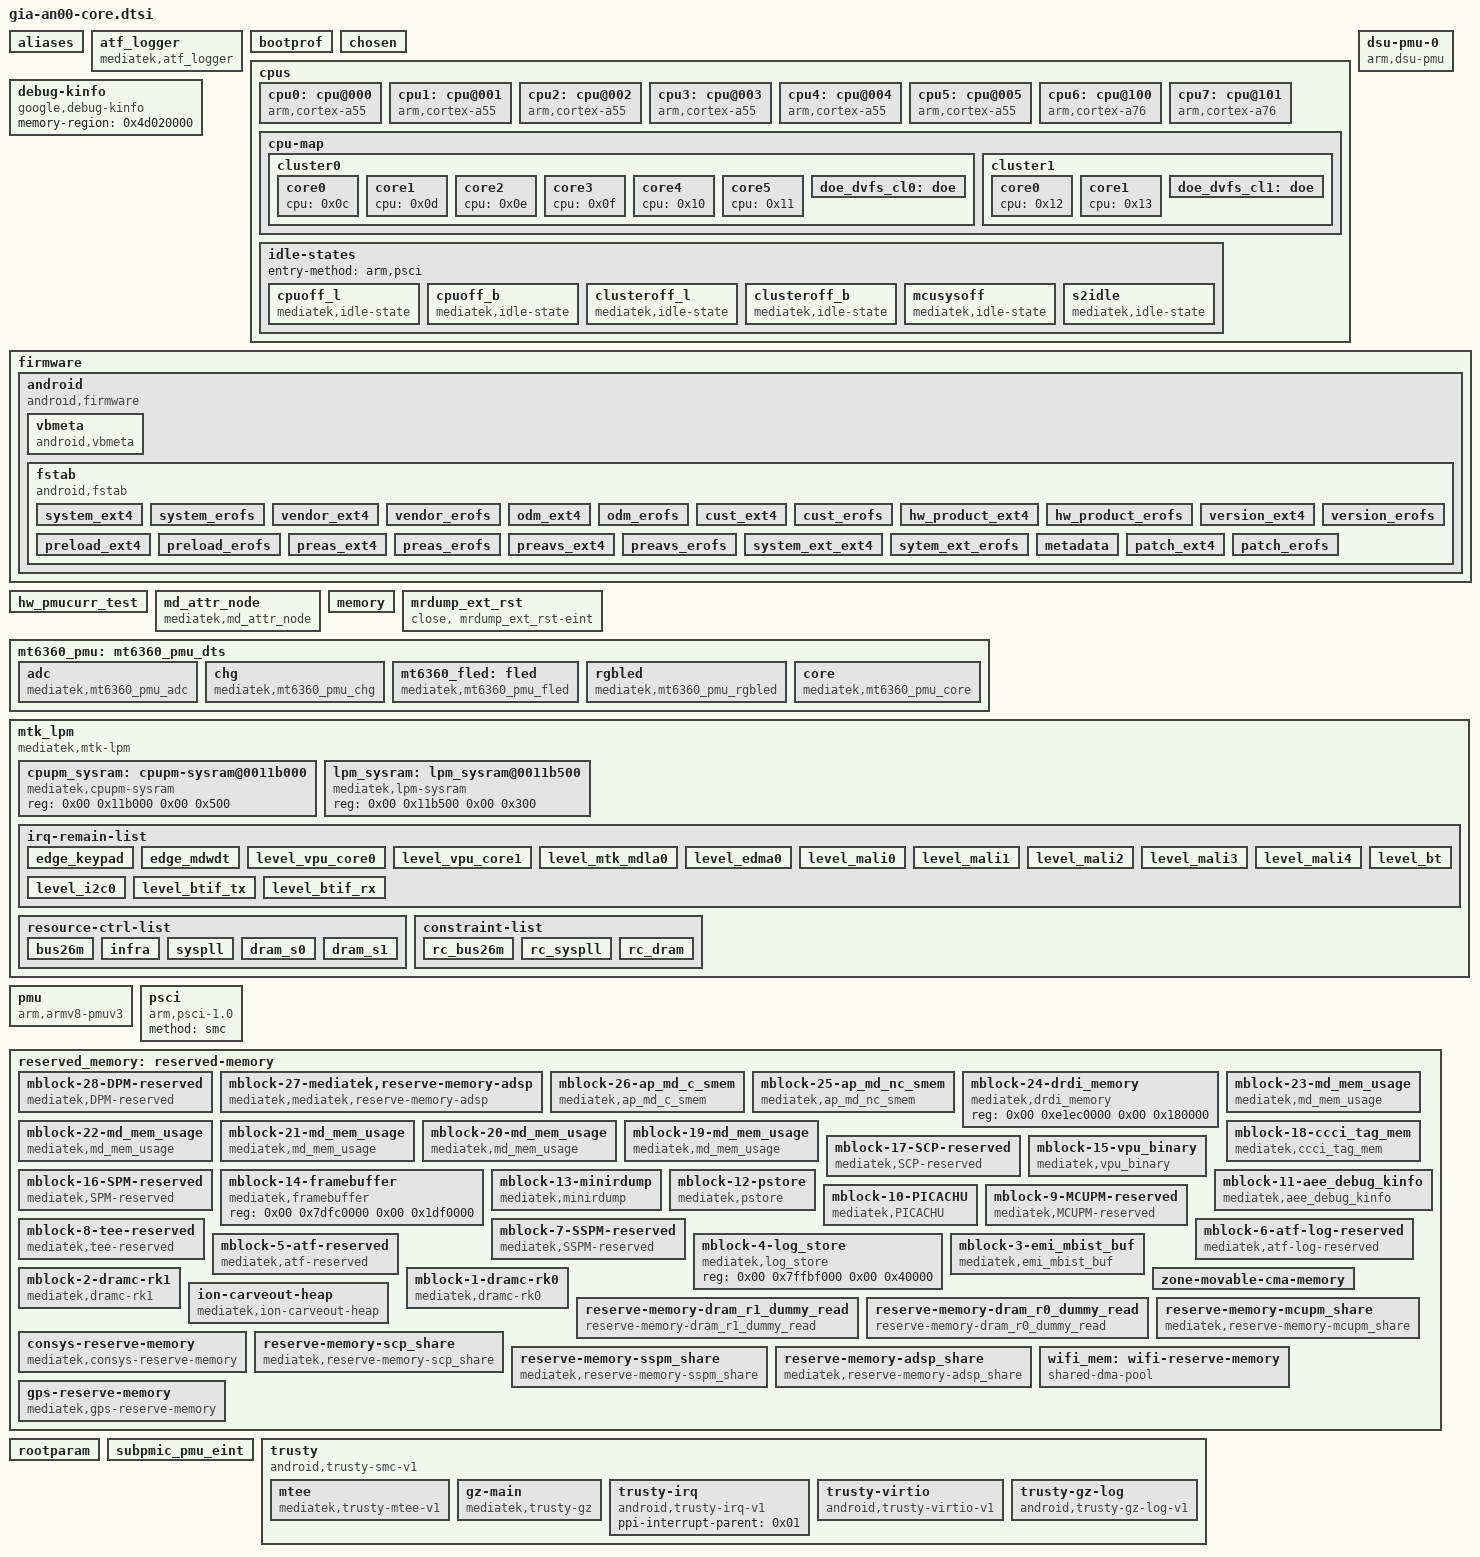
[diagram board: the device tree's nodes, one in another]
// SPDX-License-Identifier: GPL-2.0
/*
 * HONOR GIA-AN00 / MT6877V/ZA 设备树分片
 * 由实机反编译 device.dts 自动还原，节点内容保持原样
 */

/* 20 个顶层节点 */

	aliases {
			ovl0 = "/disp_ovl0@14005000";
			ovl3 = "/disp_ovl0_2l@14006000";
			ovl4 = "/disp_ovl1_2l@1401f000";
			rdma0 = "/disp_rdma0@14007000";
			dsi0 = "/dsi@14013000";
			ccorr0 = "/disp_ccorr0@1400b000";
			ccorr1 = "/disp_ccorr1@1400a000";
			mtk-msdc0 = "/msdc@11230000";
			mtk-msdc1 = "/msdc@11240000";
		};

	atf_logger {
			compatible = "mediatek,atf_logger";
		};

	bootprof {
			lk_logo_t = <0x3a7>;
			lk_t = <0x1619>;
			pl_t = <0x108f>;
		};

	chosen: chosen {
			mrdump,lk = "MRDUMP11";
			mrdump,cblock = <0x11e000 0x2000>;
			mrdump,ddr_rsv = "yes";
			aee,enable = "mini";
			atag,chipid = <0x6000000 0x59090000 0x8a0000 0xca0000 0x00>;
			linux,initrd-end = <0x5129b5be>;
			dfd,cache_dump_support = <0x01>;
			dfd,base_addr_msb = <0x8e000000>;
			dfd,base_addr = <0x00 0x8e000000>;
			non_secure_sram = <0x201100 0xe00000>;
			atag,masp = <0x16000000 0x66080041 0x11000000 0x11000000 0x1000000 0x00 0xa439f532 0xfdd77274 0xd1c98a0b 0x44a3db6c 0x31413532 0x41333637 0x43423132 0x43343538 0x992c97b6 0x168ee0c8 0x00 0x00 0x00 0x00 0x00 0x00>;
			atag,ptp = <0x6000000 0x8004154 0x00 0x00 0x00 0x00>;
			ccci,modem_info_v2 = <0xffbf 0x00 0x800a0000 0x00 0x3000000 0x14000000 0x1000000 0x00 0x00 0x00 0x00 0x00>;
			atag,mdinfo = <0x3000000 0x6080041 0x00>;
			atag,videolfb = <0xfc7d 0x00 0x1000000 0xa4170000 0xdf01 0x6c63646b 0x69745f6d 0x746b5f63 0x6f6d6d6f 0x6e5f7061 0x6e656c5f 0x64727600 0x40040000 0x38041b00 0x60091b00>;
			atag,devinfo = <0xdc000000 0x00 0x00 0x00 0x00 0x9a0800 0xc042 0x00 0x1000000 0x59090000 0x59090000 0x400ab56 0x40040000 0xaf290fd8 0x3d9bc8c 0x9179c5e9 0xd5517569 0x00 0xca0000 0x59090000 0x59090000 0x59090000 0x00 0x00 0x00 0x00 0x00 0x1000000 0x4e000000 0x59090000 0x00 0x1000000 0x00 0x7d400300 0x84000000 0x00 0x00 0x00 0x00 0x00 0x00 0x00 0x00 0x59090000 0x00 0x00 0x00 0x00 0x59090000 0x59090000 0xaa000000 0x2000200 0x00 0x9924b2d6 0xc4348f85 0xea24bdc7 0xf4348991 0xea24b3c0 0xf4348e93 0x17249f2f 0x4b246f68 0xffbf0000 0xffbf 0xffbfffbf 0xffbfffbf 0xc070c070 0x00 0x00 0x00 0x00 0x00 0x00 0x00 0x00 0x00 0x00 0x59090000 0x00 0x00 0x00 0x00 0x992c97b6 0xc5d1b92d 0x873c8d2a 0x7a4124e2 0x168ee0c8 0x2d515b4e 0x439dfcc2 0xa94b447d 0x00 0x00 0x00 0x00 0x3000000 0x00 0x00 0x00 0x00 0x00 0x59090000 0x59090000 0x10002020 0x22000015 0x16151515 0x27220000 0x80b5d65a 0x00 0x00 0x8081200 0x10000000 0xc4186384 0x86184 0x18238c 0x80182384 0xfd819700 0x00 0x00 0x3c 0xf68a0000 0xea8a000a 0xdc8800a1 0x00 0x00 0x00 0x00 0x00 0x00 0x00 0x59090000 0x59090000 0x59090000 0x00 0x00 0x00 0xa000000 0x75ed7d26 0xc8b586d6 0xf8c80820 0x3848b5 0x00 0x00 0x6700700 0xb200a00 0x59090000 0x59090000 0x59090000 0x3501c80 0x59090000 0x59090000 0x59090000 0x59090000 0x00 0x00 0x00 0x00 0x00 0x00 0x59090000 0x59090000 0x59090000 0x59090000 0x00 0x00 0x00 0x00 0x00 0x7014a018 0x4c1c2e14 0x7b18631c 0x6e3f6d3e 0x6d3e6c3f 0x12360000 0x3f3f0000 0x6576 0x79757404 0x7cfc0000 0x8b3a7b83 0xaf76b076 0xab74ab74 0x00 0x00 0x00 0x4fb47105 0x76688187 0x24c3f006 0x59090000 0x59090000 0x59090000 0x59090000 0x59090000 0x59090000 0xba880000 0x8c88000a 0xa1880079 0x418a0000 0x478a000a 0x488a007b 0x188a0000 0x198a0000 0xfe890000 0xed890000 0x5d890000 0x4f890000 0xac890000 0xb9890000 0xbb890000 0xa60a0000 0xc70a0000 0x8f0a0000 0x00 0x00 0x990c0000 0x59090000 0xcd7b97aa 0x63cb00cf 0x39cf1401 0xa049d243 0x89288a39 0xd6065517 0x9448968f 0x1bd66462>;
			atag,mem = <0x6000000 0x2004254 0x00 0x00 0x00 0x00 0x6000000 0x2004254 0x00 0x00 0x00 0x00>;
			atag,two_sec_reboot = [30];
			atag,boot_voltage = <0x33383639>;
			log_store = <0xdf1100 0x10000>;
			ram_console = <0xd01100 0x80000 0x1000000 0xc00e0000>;
			atag,shutdown_time = [30];
			atag,fg_swocv_i = [2d 33 33 38 35];
			atag,fg_swocv_v = [33 38 34 37 39];
			atag,imix_r = <0x4f000000>;
			atag,boot = <0x3000000 0x2080041 0x00 0x2000000>;
			linux,initrd-start = <0x51100000>;
			plat_dbg_info,size = <0x5c 0x2c 0x10>;
			plat_dbg_info,base = <0x11d80c 0x11d868 0x11d894>;
			plat_dbg_info,key = <0xd8a3 0xe31c 0xdb45>;
			plat_dbg_info,max = <0x03>;
			bootargs = "root=/dev/ram \t\t\tvmalloc=400M slub_debug=OFZPU swiotlb=noforce \t\t\tinitcall_debug=1 \t\t\tfirmware_class.path=/vendor/firmware \t\t\tpage_owner=on has_battery_removed=0 ramoops.mem_address=0x48090000 ramoops.mem_size=0xe0000 ramoops.pmsg_size=0x10000 ramoops.console_size=0x40000 loop.max_part=7 androidboot.boot_devices=bootdevice,soc/11230000.mmc,11230000.mmc,soc/11230000.msdc,11230000.msdc,soc/11270000.ufshci,11270000.ufshci androidboot.powerkey_restart_type=0 ramoops.mem_address=0x48090000 ramoops.mem_size=0xe0000 ramoops.pmsg_size=0x10000 ramoops.console_size=0x40000 battery_nv_sn=0000000000000000 battery_ic=5,6A922A322318AE3801002900 battery_info=AC,0,3620ACM228A0A685 battery_cert=0,0000  bootopt=64S3,32N2,64N2 buildvariant=user root=/dev/ram androidboot.slot_suffix=_b androidboot.slot=b androidboot.veritymode=enforcing androidboot.vbmeta.avb_version=1.2 root=/dev/ram androidboot.verifiedbootstate=orange androidboot.swtype=normal fg_cali=0xedd4e,0x0,0xf4734,0x0,0x0,0x0,0x0,0x0 androidboot.hwsim=default  start_mcs_flag=false TP_COLOR=0 devmodel=GIA-AN00 vendorcountry=all/cn oba_version=20260410061949_OBA_VERSION androidboot.atm=disabled enter_recovery=0 usb_macbt=normal boot_detector_enable=1  boot_recovery_enable=1  androidboot.meta_log_disable=0 efuse_sla_status=1 mtk_printk_ctrl.disable_uart=1 androidboot.serialno=0000000000000000 androidboot.product.hardware.sku=GIA-AN00 userlock=locked  androidboot.oemmode=rd    androidboot.bootreason=normalboot reboot_reason=normalboot gpt=1 usb2jtag_mode=0 androidboot.dtb_idx=0 androidboot.dtbo_idx=6";
			kaslr-seed = <0x00 0x00>;
			phandle = <0xe4>;
			atag,videolfb-fb_base_l = "~`P";
			atag,videolfb-fb_base_h = <0x00>;
			atag,videolfb-islcmfound = <0x01>;
			atag,videolfb-islcm_inited = <0x00>;
			atag,videolfb-fps = <0x1770>;
			atag,videolfb-vramSize = <0x1be0000>;
			atag,videolfb-lcmname = "nt35595_fhd_dsi_cmd_truly_nt50358_drv";
		};

	cpus {
			#address-cells = <0x01>;
			#size-cells = <0x00>;
	
			cpu0: cpu@000 {
				device_type = "cpu";
				compatible = "arm,cortex-a55";
				reg = <0x00>;
				enable-method = "psci";
				clock-frequency = <0x77359400>;
				cpu-idle-states = <0x06 0x07 0x08 0x09>;
				phandle = <0x0c>;
			};
	
			cpu1: cpu@001 {
				device_type = "cpu";
				compatible = "arm,cortex-a55";
				reg = <0x100>;
				enable-method = "psci";
				clock-frequency = <0x77359400>;
				cpu-idle-states = <0x06 0x07 0x08 0x09>;
				phandle = <0x0d>;
			};
	
			cpu2: cpu@002 {
				device_type = "cpu";
				compatible = "arm,cortex-a55";
				reg = <0x200>;
				enable-method = "psci";
				clock-frequency = <0x77359400>;
				cpu-idle-states = <0x06 0x07 0x08 0x09>;
				phandle = <0x0e>;
			};
	
			cpu3: cpu@003 {
				device_type = "cpu";
				compatible = "arm,cortex-a55";
				reg = <0x300>;
				enable-method = "psci";
				clock-frequency = <0x77359400>;
				cpu-idle-states = <0x06 0x07 0x08 0x09>;
				phandle = <0x0f>;
			};
	
			cpu4: cpu@004 {
				device_type = "cpu";
				compatible = "arm,cortex-a55";
				reg = <0x400>;
				enable-method = "psci";
				clock-frequency = <0x77359400>;
				cpu-idle-states = <0x06 0x07 0x08 0x09>;
				phandle = <0x10>;
			};
	
			cpu5: cpu@005 {
				device_type = "cpu";
				compatible = "arm,cortex-a55";
				reg = <0x500>;
				enable-method = "psci";
				clock-frequency = <0x77359400>;
				cpu-idle-states = <0x06 0x07 0x08 0x09>;
				phandle = <0x11>;
			};
	
			cpu6: cpu@100 {
				device_type = "cpu";
				compatible = "arm,cortex-a76";
				reg = <0x600>;
				enable-method = "psci";
				clock-frequency = <0x77359400>;
				cpu-idle-states = <0x0a 0x0b 0x08 0x09>;
				phandle = <0x12>;
			};
	
			cpu7: cpu@101 {
				device_type = "cpu";
				compatible = "arm,cortex-a76";
				reg = <0x700>;
				enable-method = "psci";
				clock-frequency = <0x77359400>;
				cpu-idle-states = <0x0a 0x0b 0x08 0x09>;
				phandle = <0x13>;
			};
	
			cpu-map {
	
				cluster0 {
	
					core0 {
						cpu = <0x0c>;
					};
	
					core1 {
						cpu = <0x0d>;
					};
	
					core2 {
						cpu = <0x0e>;
					};
	
					core3 {
						cpu = <0x0f>;
					};
	
					core4 {
						cpu = <0x10>;
					};
	
					core5 {
						cpu = <0x11>;
					};
	
					doe_dvfs_cl0: doe {
						phandle = <0xe5>;
					};
				};
	
				cluster1 {
	
					core0 {
						cpu = <0x12>;
					};
	
					core1 {
						cpu = <0x13>;
					};
	
					doe_dvfs_cl1: doe {
						phandle = <0xe6>;
					};
				};
			};
	
			idle-states {
				entry-method = "arm,psci";
	
				cpuoff_l: cpuoff_l {
					compatible = "mediatek,idle-state";
					arm,psci-suspend-param = <0x10001>;
					local-timer-stop;
					entry-latency-us = <0x32>;
					exit-latency-us = <0x64>;
					min-residency-us = <0x640>;
					phandle = <0x06>;
				};
	
				cpuoff_b: cpuoff_b {
					compatible = "mediatek,idle-state";
					arm,psci-suspend-param = <0x10001>;
					local-timer-stop;
					entry-latency-us = <0x32>;
					exit-latency-us = <0x64>;
					min-residency-us = <0x578>;
					phandle = <0x0a>;
				};
	
				clusteroff_l: clusteroff_l {
					compatible = "mediatek,idle-state";
					arm,psci-suspend-param = <0x1010001>;
					local-timer-stop;
					entry-latency-us = <0x64>;
					exit-latency-us = <0xfa>;
					min-residency-us = <0x834>;
					phandle = <0x07>;
				};
	
				clusteroff_b: clusteroff_b {
					compatible = "mediatek,idle-state";
					arm,psci-suspend-param = <0x1010001>;
					local-timer-stop;
					entry-latency-us = <0x64>;
					exit-latency-us = <0xfa>;
					min-residency-us = <0x76c>;
					phandle = <0x0b>;
				};
	
				mcusysoff: mcusysoff {
					compatible = "mediatek,idle-state";
					arm,psci-suspend-param = <0x1010002>;
					local-timer-stop;
					entry-latency-us = <0x12c>;
					exit-latency-us = <0x4b0>;
					min-residency-us = <0xa28>;
					phandle = <0x08>;
				};
	
				s2idle: s2idle {
					compatible = "mediatek,idle-state";
					arm,psci-suspend-param = <0x1010100>;
					local-timer-stop;
					entry-latency-us = <0x1f4>;
					exit-latency-us = <0x578>;
					min-residency-us = <0xffffffff>;
					phandle = <0x09>;
				};
			};
		};

	debug-kinfo {
			memory-region = <0x4d020000>;
			compatible = "google,debug-kinfo";
		};

	dsu-pmu-0 {
			compatible = "arm,dsu-pmu";
			interrupts = <0x00 0x12 0x04>;
			cpus = <0x0c 0x0d 0x0e 0x0f 0x10 0x11 0x12 0x13>;
		};

	firmware {
	
			android {
				mode = "normal";
				serialno = "0000000000000000";
				hardware = "mt6877";
				vbmeta.digest = "26cabf14be922ae3c91020e367ab8466afb57b97a70f36fd0d32d0bc6ac9ac50";
				vbmeta.size = "30592";
				vbmeta.hash_alg = "sha256";
				compatible = "android,firmware";
	
				vbmeta {
					compatible = "android,vbmeta";
					parts = "vbmeta,boot,ramdisk,eng_system,eng_vendor,vbmeta_system,vbmeta_vendor,vbmeta_odm,vbmeta_hw_product,vbmeta_preas,vbmeta_preavs,vbmeta_cust,vbmeta_version,vbmeta_preload,vbmeta_system_ext";
					ta_parts = "boot,ramdisk,vbmeta_system,vbmeta_vendor,vbmeta_odm,vbmeta_hw_product,vbmeta_preas,vbmeta_preavs,vbmeta_cust,vbmeta_system_ext";
				};
	
				fstab {
					compatible = "android,fstab";
	
					system_ext4 {
						mnt_point = "/system";
						dev = "system";
						type = "ext4";
						mnt_flags = "ro";
						fsmgr_flags = "wait,logical,slotselect,first_stage_mount,avb";
						status = "ok";
					};
	
					system_erofs {
						mnt_point = "/system";
						dev = "system";
						type = "erofs";
						mnt_flags = "ro";
						fsmgr_flags = "wait,logical,slotselect,first_stage_mount,avb";
						status = "ok";
					};
	
					vendor_ext4 {
						mnt_point = "/vendor";
						dev = "vendor";
						type = "ext4";
						mnt_flags = "ro";
						fsmgr_flags = "wait,logical,slotselect,first_stage_mount,avb";
						status = "ok";
					};
	
					vendor_erofs {
						mnt_point = "/vendor";
						dev = "vendor";
						type = "erofs";
						mnt_flags = "ro";
						fsmgr_flags = "wait,logical,slotselect,first_stage_mount,avb";
						status = "ok";
					};
	
					odm_ext4 {
						mnt_point = "/odm";
						dev = "odm";
						type = "ext4";
						mnt_flags = "ro";
						fsmgr_flags = "wait,logical,slotselect,first_stage_mount,avb";
						status = "ok";
					};
	
					odm_erofs {
						mnt_point = "/odm";
						dev = "odm";
						type = "erofs";
						mnt_flags = "ro";
						fsmgr_flags = "wait,logical,slotselect,first_stage_mount,avb";
						status = "ok";
					};
	
					cust_ext4 {
						mnt_point = "/cust";
						dev = "cust";
						type = "ext4";
						mnt_flags = "ro";
						fsmgr_flags = "wait,nofail,logical,slotselect,first_stage_mount,avb";
						status = "ok";
					};
	
					cust_erofs {
						mnt_point = "/cust";
						dev = "cust";
						type = "erofs";
						mnt_flags = "ro";
						fsmgr_flags = "wait,nofail,logical,slotselect,first_stage_mount,avb";
						status = "ok";
					};
	
					hw_product_ext4 {
						mnt_point = "/product_h";
						dev = "hw_product";
						type = "ext4";
						mnt_flags = "ro";
						fsmgr_flags = "wait,nofail,logical,slotselect,first_stage_mount,avb";
						status = "ok";
					};
	
					hw_product_erofs {
						mnt_point = "/product_h";
						dev = "hw_product";
						type = "erofs";
						mnt_flags = "ro";
						fsmgr_flags = "wait,nofail,logical,slotselect,first_stage_mount,avb";
						status = "ok";
					};
	
					version_ext4 {
						mnt_point = "/version";
						dev = "version";
						type = "ext4";
						mnt_flags = "ro";
						fsmgr_flags = "wait,nofail,logical,slotselect,first_stage_mount,avb";
						status = "ok";
					};
	
					version_erofs {
						mnt_point = "/version";
						dev = "version";
						type = "erofs";
						mnt_flags = "ro";
						fsmgr_flags = "wait,nofail,logical,slotselect,first_stage_mount,avb";
						status = "ok";
					};
	
					preload_ext4 {
						mnt_point = "/preload";
						dev = "preload";
						type = "ext4";
						mnt_flags = "ro";
						fsmgr_flags = "wait,nofail,logical,slotselect,first_stage_mount,avb";
						status = "ok";
					};
	
					preload_erofs {
						mnt_point = "/preload";
						dev = "preload";
						type = "erofs";
						mnt_flags = "ro";
						fsmgr_flags = "wait,nofail,logical,slotselect,first_stage_mount,avb";
						status = "ok";
					};
	
					preas_ext4 {
						mnt_point = "/preas";
						dev = "preas";
						type = "ext4";
						mnt_flags = "ro";
						fsmgr_flags = "wait,nofail,logical,slotselect,first_stage_mount,avb";
						status = "ok";
					};
	
					preas_erofs {
						mnt_point = "/preas";
						dev = "preas";
						type = "erofs";
						mnt_flags = "ro";
						fsmgr_flags = "wait,nofail,logical,slotselect,first_stage_mount,avb";
						status = "ok";
					};
	
					preavs_ext4 {
						mnt_point = "/vendor/preavs";
						dev = "preavs";
						type = "ext4";
						mnt_flags = "ro";
						fsmgr_flags = "wait,nofail,logical,slotselect,first_stage_mount,avb";
						status = "ok";
					};
	
					preavs_erofs {
						mnt_point = "/vendor/preavs";
						dev = "preavs";
						type = "erofs";
						mnt_flags = "ro";
						fsmgr_flags = "wait,nofail,logical,slotselect,first_stage_mount,avb";
						status = "ok";
					};
	
					system_ext_ext4 {
						mnt_point = "/system_ext";
						dev = "system_ext";
						type = "ext4";
						mnt_flags = "ro";
						fsmgr_flags = "wait,nofail,logical,slotselect,first_stage_mount,avb";
						status = "ok";
					};
	
					sytem_ext_erofs {
						mnt_point = "/system_ext";
						dev = "system_ext";
						type = "erofs";
						mnt_flags = "ro";
						fsmgr_flags = "wait,nofail,logical,slotselect,first_stage_mount,avb";
						status = "ok";
					};
	
					metadata {
						mnt_point = "/metadata";
						dev = "/dev/block/by-name/metadata";
						type = "ext4";
						mnt_flags = "rw,noatime,nosuid,nodev,discard";
						fsmgr_flags = "wait,check,formattable,first_stage_mount";
						status = "ok";
					};
	
					patch_ext4 {
						mnt_point = "/patch_hn";
						dev = "/dev/block/by-name/patch";
						type = "ext4";
						mnt_flags = "ro";
						fsmgr_flags = "wait,nofail,slotselect,avb_keys=/patch_avb_key,first_stage_mount";
						status = "ok";
					};
	
					patch_erofs {
						mnt_point = "/patch_hn";
						dev = "/dev/block/by-name/patch";
						type = "erofs";
						mnt_flags = "ro";
						fsmgr_flags = "wait,nofail,slotselect,avb_keys=/patch_avb_key,first_stage_mount";
						status = "ok";
					};
				};
			};
		};

	hw_pmucurr_test: hw_pmucurr_test {
			power_address = "1AB0 1AC4 1AD8 1AEC 1A44 1A9C 1A88 1A6C";
			phandle = <0xc7>;
		};

	md_attr_node {
			mediatek,md_product_name_model_id = <0xf0f0f0f>;
			mediatek,md_drdi_rf_set_idx = <0xf0f0f0f>;
			compatible = "mediatek,md_attr_node";
		};

	memory {
			tee_reserved_mem = <0xfc6f 0x00 0x2403 0x00>;
			lca_reserved_mem = <0x00 0x00 0x00 0x00>;
			mblock_info = <0x19000000 0x00 0x40 0x00 0x800 0x00 0x00 0x00 0xd047 0x00 0x3800 0x00 0x00 0x00 0x1848 0x00 0x800 0x00 0x00 0x00 0xb048 0x00 0x1000 0x00 0x00 0x00 0xe048 0x00 0x1000 0x00 0x00 0x00 0x705a 0x00 0x9015 0x00 0x00 0x00 0x2473 0x00 0xdb04 0x00 0x00 0x00 0x78 0x00 0x02 0x00 0x00 0x00 0x927a 0x00 0xca01 0x00 0x00 0x00 0x60fb7c 0x00 0xa00000 0x00 0x00 0x00 0xfb7f 0x00 0xf00000 0x00 0x00 0x00 0x80 0x00 0x0a 0x00 0x00 0x00 0x968c 0x00 0x6a01 0x00 0x00 0x00 0x1d8e 0x00 0x232a 0x00 0x00 0x00 0x80b8 0x00 0xd00 0x00 0x00 0x00 0xd8bf 0x00 0x800 0x00 0x00 0x00 0xe4bf 0x00 0x1b00 0x00 0x00 0x00 0xc0 0x00 0x20 0x00 0x00 0x00 0x4e2 0x00 0x00 0x00 0x00 0x00 0x5e2 0x00 0xfb00 0x00 0x00 0x00 0x15e3 0x00 0xeb00 0x00 0x00 0x00 0x82eb 0x00 0x960f 0x00 0x00 0x00 0x30fd 0x00 0xb602 0x00 0x00 0x00 0xffff 0x00 0xf00040 0x00 0x00 0x00 0x40 0x1000000 0xf0ffff 0x00 0x1000000 0x00 0x00 0x00 0x00 0x00 0x00 0x00 0x00 0x00 0x00 0x00 0x00 0x00 0x00 0x00 0x00 0x00 0x00 0x00 0x00 0x00 0x00 0x00 0x00 0x00 0x00 0x00 0x00 0x00 0x00 0x00 0x00 0x00 0x00 0x00 0x00 0x00 0x00 0x00 0x00 0x00 0x00 0x00 0x00 0x00 0x00 0x00 0x00 0x00 0x00 0x00 0x00 0x00 0x00 0x00 0x00 0x00 0x00 0x00 0x00 0x00 0x00 0x00 0x00 0x00 0x00 0x00 0x00 0x00 0x00 0x00 0x00 0x00 0x00 0x00 0x00 0x00 0x00 0x00 0x00 0x00 0x00 0x00 0x00 0x00 0x00 0x00 0x00 0x00 0x00 0x00 0x00 0x00 0x00 0x00 0x00 0x00 0x00 0x00 0x00 0x00 0x00 0x00 0x00 0x00 0x00 0x00 0x00 0x00 0x00 0x00 0x00 0x00 0x00 0x00 0x00 0x00 0x00 0x00 0x00 0x00 0x00 0x00 0x00 0x00 0x00 0x00 0x00 0x00 0x00 0x00 0x00 0x00 0x00 0x00 0x00 0x00 0x00 0x00 0x00 0x00 0x00 0x00 0x00 0x00 0x00 0x00 0x00 0x00 0x00 0x00 0x00 0x00 0x00 0x00 0x00 0x00 0x00 0x00 0x00 0x00 0x00 0x00 0x00 0x00 0x00 0x00 0x00 0x00 0x00 0x00 0x00 0x00 0x00 0x00 0x00 0x00 0x00 0x00 0x00 0x00 0x00 0x00 0x00 0x00 0x00 0x00 0x00 0x00 0x00 0x00 0x00 0x00 0x00 0x00 0x00 0x00 0x00 0x00 0x00 0x00 0x00 0x00 0x00 0x00 0x00 0x00 0x00 0x00 0x00 0x00 0x00 0x00 0x00 0x00 0x00 0x00 0x00 0x00 0x00 0x00 0x00 0x00 0x00 0x00 0x00 0x00 0x00 0x00 0x00 0x00 0x00 0x00 0x00 0x00 0x00 0x00 0x00 0x00 0x00 0x00 0x00 0x00 0x00 0x00 0x00 0x00 0x00 0x00 0x00 0x00 0x00 0x00 0x00 0x00 0x00 0x00 0x00 0x00 0x00 0x00 0x00 0x00 0x00 0x00 0x00 0x00 0x00 0x00 0x00 0x00 0x00 0x00 0x00 0x00 0x00 0x00 0x00 0x00 0x00 0x00 0x00 0x00 0x00 0x00 0x00 0x00 0x00 0x00 0x00 0x00 0x00 0x00 0x00 0x00 0x00 0x00 0x00 0x00 0x00 0x00 0x00 0x00 0x00 0x00 0x00 0x00 0x00 0x00 0x00 0x00 0x00 0x00 0x00 0x00 0x00 0x00 0x00 0x00 0x00 0x00 0x00 0x00 0x00 0x00 0x00 0x00 0x00 0x00 0x00 0x00 0x00 0x00 0x00 0x00 0x00 0x00 0x00 0x00 0x00 0x00 0x00 0x00 0x00 0x00 0x00 0x00 0x00 0x00 0x00 0x00 0x00 0x00 0x00 0x00 0x00 0x00 0x00 0x00 0x00 0x00 0x00 0x00 0x00 0x00 0x00 0x00 0x00 0x00 0x00 0x00 0x00 0x00 0x00 0x00 0x00 0x00 0x00 0x00 0x00 0x00 0x00 0x00 0x00 0x00 0x00 0x00 0x00 0x00 0x00 0x00 0x00 0x00 0x00 0x00 0x00 0x00 0x00 0x00 0x00 0x00 0x00 0x00 0x00 0x00 0x00 0x00 0x00 0x00 0x00 0x00 0x00 0x00 0x00 0x00 0x00 0x00 0x00 0x00 0x00 0x00 0x00 0x00 0x00 0x00 0x00 0x00 0x00 0x00 0x00 0x00 0x00 0x00 0x00 0x00 0x00 0x00 0x00 0x00 0x00 0x00 0x00 0x00 0x00 0x00 0x00 0x00 0x00 0x00 0x00 0x00 0x00 0x00 0x00 0x00 0x00 0x00 0x00 0x00 0x00 0x00 0x00 0x00 0x00 0x00 0x00 0x00 0x00 0x00 0x00 0x00 0x00 0x00 0x00 0x00 0x00 0x00 0x00 0x00 0x00 0x00 0x00 0x00 0x00 0x00 0x00 0x00 0x00 0x00 0x00 0x00 0x00 0x00 0x00 0x00 0x00 0x00 0x00 0x00 0x00 0x00 0x00 0x00 0x00 0x00 0x00 0x00 0x00 0x00 0x00 0x00 0x00 0x00 0x00 0x00 0x00 0x00 0x00 0x00 0x00 0x00 0x00 0x00 0x00 0x00 0x00 0x00 0x00 0x00 0x00 0x00 0x00 0x00 0x00 0x00 0x00 0x00 0x00 0x00 0x00 0x00 0x00 0x00 0x00 0x00 0x00 0x00 0x00 0x00 0x00 0x00 0x00 0x00 0x00 0x00 0x00 0x00 0x00 0x00 0x00 0x00 0x00 0x00 0x00 0x00 0x00 0x00 0x00 0x00 0x00 0x00 0x00 0x00 0x00 0x00 0x00 0x00 0x00 0x00 0x00 0x00 0x00 0x00 0x00 0x00 0x00 0x00 0x00 0x00 0x00 0x00 0x00 0x00 0x00 0x00 0x00 0x00 0x00 0x00 0x00 0x00 0x00 0x00 0x00 0x00 0x00 0x00 0x00 0x00 0x00 0x00 0x00 0x00 0x00 0x00 0x00 0x00 0x00 0x00 0x99999999 0x2000000 0x26000000 0x00 0xf0ff3f 0x1000000 0x100000 0x00 0x00 0x6472616d 0x632d726b 0x30000000 0x00 0x00 0x00 0x00 0x00 0x00 0x00 0x00 0x00 0x00 0x00 0x00 0x00 0x00 0x00 0x00 0x00 0x00 0x00 0x00 0x00 0x00 0x00 0x00 0x00 0x00 0x00 0x00 0x00 0x00 0xf0ff3f 0x2000000 0x100000 0x00 0x00 0x6472616d 0x632d726b 0x31000000 0x00 0x00 0x00 0x00 0x00 0x00 0x00 0x00 0x00 0x00 0x00 0x00 0x00 0x00 0x00 0x00 0x00 0x00 0x00 0x00 0x00 0x00 0x00 0x00 0x00 0x00 0x00 0x00 0x00 0x00 0xf0ff7f 0x00 0x100000 0x00 0x00 0x656d695f 0x6d626973 0x745f6275 0x66000000 0x00 0x00 0x00 0x00 0x00 0x00 0x00 0x00 0x00 0x00 0x00 0x00 0x00 0x00 0x00 0x00 0x00 0x00 0x00 0x00 0x00 0x00 0x00 0x00 0x00 0x00 0x00 0x00 0x00 0xf0fb7f 0x00 0x400 0x00 0x1000000 0x6c6f675f 0x73746f72 0x65000000 0x00 0x00 0x00 0x00 0x00 0x00 0x00 0x00 0x00 0x00 0x00 0x00 0x00 0x00 0x00 0x00 0x00 0x00 0x00 0x00 0x00 0x00 0x00 0x00 0x00 0x00 0x00 0x00 0x00 0x00 0xc048 0x00 0x2000 0x00 0x00 0x6174662d 0x72657365 0x72766564 0x00 0x00 0x00 0x00 0x00 0x00 0x00 0x00 0x00 0x00 0x00 0x00 0x00 0x00 0x00 0x00 0x00 0x00 0x00 0x00 0x00 0x00 0x00 0x00 0x00 0x00 0x00 0x00 0x00 0x00 0xe0bf 0x00 0x400 0x00 0x00 0x6174662d 0x6c6f672d 0x72657365 0x72766564 0x00 0x00 0x00 0x00 0x00 0x00 0x00 0x00 0x00 0x00 0x00 0x00 0x00 0x00 0x00 0x00 0x00 0x00 0x00 0x00 0x00 0x00 0x00 0x00 0x00 0x00 0x00 0x00 0x00 0xeb7f 0x00 0x1000 0x00 0x00 0x5353504d 0x2d726573 0x65727665 0x64000000 0x00 0x00 0x00 0x00 0x00 0x00 0x00 0x00 0x00 0x00 0x00 0x00 0x00 0x00 0x00 0x00 0x00 0x00 0x00 0x00 0x00 0x00 0x00 0x00 0x00 0x00 0x00 0x00 0x00 0x70 0x00 0x2403 0x00 0x00 0x7465652d 0x72657365 0x72766564 0x00 0x00 0x00 0x00 0x00 0x00 0x00 0x00 0x00 0x00 0x00 0x00 0x00 0x00 0x00 0x00 0x00 0x00 0x00 0x00 0x00 0x00 0x00 0x00 0x00 0x00 0x00 0x00 0x00 0x00 0xdb7f 0x00 0x1000 0x00 0x00 0x4d435550 0x4d2d7265 0x73657276 0x65640000 0x00 0x00 0x00 0x00 0x00 0x00 0x00 0x00 0x00 0x00 0x00 0x00 0x00 0x00 0x00 0x00 0x00 0x00 0x00 0x00 0x00 0x00 0x00 0x00 0x00 0x00 0x00 0x00 0x00 0xd0bf 0x00 0x800 0x00 0x00 0x50494341 0x43485500 0x00 0x00 0x00 0x00 0x00 0x00 0x00 0x00 0x00 0x00 0x00 0x00 0x00 0x00 0x00 0x00 0x00 0x00 0x00 0x00 0x00 0x00 0x00 0x00 0x00 0x00 0x00 0x00 0x00 0x00 0x00 0x848 0x00 0x100 0x00 0x00 0x6165655f 0x64656275 0x675f6b69 0x6e666f00 0x00 0x00 0x00 0x00 0x00 0x00 0x00 0x00 0x00 0x00 0x00 0x00 0x00 0x00 0x00 0x00 0x00 0x00 0x00 0x00 0x00 0x00 0x00 0x00 0x00 0x00 0x00 0x00 0x00 0x948 0x00 0xe00 0x00 0x00 0x7073746f 0x72650000 0x00 0x00 0x00 0x00 0x00 0x00 0x00 0x00 0x00 0x00 0x00 0x00 0x00 0x00 0x00 0x00 0x00 0x00 0x00 0x00 0x00 0x00 0x00 0x00 0x00 0x00 0x00 0x00 0x00 0x00 0x00 0x1748 0x00 0x100 0x00 0x00 0x6d696e69 0x7264756d 0x70000000 0x00 0x00 0x00 0x00 0x00 0x00 0x00 0x00 0x00 0x00 0x00 0x00 0x00 0x00 0x00 0x00 0x00 0x00 0x00 0x00 0x00 0x00 0x00 0x00 0x00 0x00 0x00 0x00 0x00 0x00 0xf048 0x00 0x1000 0x00 0x1000000 0x706c2d64 0x72616d62 0x75660000 0x00 0x00 0x00 0x00 0x00 0x00 0x00 0x00 0x00 0x00 0x00 0x00 0x00 0x00 0x00 0x00 0x00 0x00 0x00 0x00 0x00 0x00 0x00 0x00 0x00 0x00 0x00 0x00 0x00 0x00 0x49 0x00 0x1000 0x00 0x1000000 0x706c2d62 0x6f6f7474 0x61670000 0x00 0x00 0x00 0x00 0x00 0x00 0x00 0x00 0x00 0x00 0x00 0x00 0x00 0x00 0x00 0x00 0x00 0x00 0x00 0x00 0x00 0x00 0x00 0x00 0x00 0x00 0x00 0x00 0x00 0x00 0x90b9 0x00 0x4006 0x00 0x00 0x6c6b5f68 0x6561705f 0x6d626c6f 0x636b0000 0x00 0x00 0x00 0x00 0x00 0x00 0x00 0x00 0x00 0x00 0x00 0x00 0x00 0x00 0x00 0x00 0x00 0x00 0x00 0x00 0x00 0x00 0x00 0x00 0x00 0x00 0x00 0x00 0x00 0x2048 0x00 0x9000 0x00 0x00 0x6c6b5f61 0x6464725f 0x6d620000 0x00 0x00 0x00 0x00 0x00 0x00 0x00 0x00 0x00 0x00 0x00 0x00 0x00 0x00 0x00 0x00 0x00 0x00 0x00 0x00 0x00 0x00 0x00 0x00 0x00 0x00 0x00 0x00 0x00 0x00 0x1049 0x00 0x08 0x00 0x00 0x73637261 0x7463685f 0x61646472 0x5f6d6200 0x00 0x00 0x00 0x00 0x00 0x00 0x00 0x00 0x00 0x00 0x00 0x00 0x00 0x00 0x00 0x00 0x00 0x00 0x00 0x00 0x00 0x00 0x00 0x00 0x00 0x00 0x00 0x00 0x00 0xfc7d 0x00 0xdf01 0x00 0x1000000 0x6672616d 0x65627566 0x66657200 0x00 0x00 0x00 0x00 0x00 0x00 0x00 0x00 0x00 0x00 0x00 0x00 0x00 0x00 0x00 0x00 0x00 0x00 0x00 0x00 0x00 0x00 0x00 0x00 0x00 0x00 0x00 0x00 0x00 0x00 0xfc7c 0x00 0x01 0x00 0x00 0x6c6f676f 0x5f64625f 0x61646472 0x5f706100 0x00 0x00 0x00 0x00 0x00 0x00 0x00 0x00 0x00 0x00 0x00 0x00 0x00 0x00 0x00 0x00 0x00 0x00 0x00 0x00 0x00 0x00 0x00 0x00 0x00 0x00 0x00 0x00 0x00 0x5c7c 0x00 0x609f00 0x00 0x00 0x74656d70 0x66625f61 0x64647200 0x00 0x00 0x00 0x00 0x00 0x00 0x00 0x00 0x00 0x00 0x00 0x00 0x00 0x00 0x00 0x00 0x00 0x00 0x00 0x00 0x00 0x00 0x00 0x00 0x00 0x00 0x00 0x00 0x00 0x00 0xc847 0x00 0x800 0x00 0x1000000 0x6474625f 0x6b65726e 0x656c5f61 0x6464725f 0x6d620000 0x00 0x00 0x00 0x00 0x00 0x00 0x00 0x00 0x00 0x00 0x00 0x00 0x00 0x00 0x00 0x00 0x00 0x00 0x00 0x00 0x00 0x00 0x00 0x00 0x00 0x00 0x00 0x00 0x840 0x00 0xc007 0x00 0x00 0x6b65726e 0x656c5f61 0x6464725f 0x6d620000 0x00 0x00 0x00 0x00 0x00 0x00 0x00 0x00 0x00 0x00 0x00 0x00 0x00 0x00 0x00 0x00 0x00 0x00 0x00 0x00 0x00 0x00 0x00 0x00 0x00 0x00 0x00 0x00 0x00 0x1051 0x00 0x6009 0x00 0x00 0x72616d64 0x69736b5f 0x61646472 0x5f6d6200 0x00 0x00 0x00 0x00 0x00 0x00 0x00 0x00 0x00 0x00 0x00 0x00 0x00 0x00 0x00 0x00 0x00 0x00 0x00 0x00 0x00 0x00 0x00 0x00 0x00 0x00 0x00 0x00 0x00 0x8db8 0x00 0x301 0x00 0x00 0x7670755f 0x62696e61 0x72790000 0x00 0x00 0x00 0x00 0x00 0x00 0x00 0x00 0x00 0x00 0x00 0x00 0x00 0x00 0x00 0x00 0x00 0x00 0x00 0x00 0x00 0x00 0x00 0x00 0x00 0x00 0x00 0x00 0x00 0x00 0xff77 0x00 0x100 0x00 0x00 0x53504d2d 0x72657365 0x72766564 0x00 0x00 0x00 0x00 0x00 0x00 0x00 0x00 0x00 0x00 0x00 0x00 0x00 0x00 0x00 0x00 0x00 0x00 0x00 0x00 0x00 0x00 0x00 0x00 0x00 0x00 0x00 0x00 0x00 0x00 0x40b8 0x00 0x4000 0x00 0x00 0x5343502d 0x72657365 0x72766564 0x00 0x00 0x00 0x00 0x00 0x00 0x00 0x00 0x00 0x00 0x00 0x00 0x00 0x00 0x00 0x00 0x00 0x00 0x00 0x00 0x00 0x00 0x00 0x00 0x00 0x00 0x00 0x00 0x00 0x00 0xffbf 0x00 0x100 0x00 0x00 0x63636369 0x5f746167 0x5f6d656d 0x00 0x00 0x00 0x00 0x00 0x00 0x00 0x00 0x00 0x00 0x00 0x00 0x00 0x00 0x00 0x00 0x00 0x00 0x00 0x00 0x00 0x00 0x00 0x00 0x00 0x00 0x00 0x00 0x00 0x00 0xe0 0x00 0xec01 0x00 0x00 0x6d645f6d 0x656d5f75 0x73616765 0x00 0x00 0x00 0x00 0x00 0x00 0x00 0x00 0x00 0x00 0x00 0x00 0x00 0x00 0x00 0x00 0x00 0x00 0x00 0x00 0x00 0x00 0x00 0x00 0x00 0x00 0x00 0x00 0x00 0x00 0x4e2 0x00 0x100 0x00 0x00 0x6d645f6d 0x656d5f75 0x73616765 0x00 0x00 0x00 0x00 0x00 0x00 0x00 0x00 0x00 0x00 0x00 0x00 0x00 0x00 0x00 0x00 0x00 0x00 0x00 0x00 0x00 0x00 0x00 0x00 0x00 0x00 0x00 0x00 0x00 0x989b4548 0xe3 0x00 0x1500 0x00 0x00 0x6d645f6d 0x656d5f75 0x73616765 0x00 0x00 0x00 0x00 0x00 0x00 0x00 0x00 0x00 0x00 0x00 0x00 0x00 0x00 0x00 0x00 0x00 0x00 0x00 0x00 0x00 0x00 0x00 0x00 0x00 0x00 0x00 0x00 0x00 0xfb00 0xe4 0x00 0x8207 0x00 0x00 0x6d645f6d 0x656d5f75 0x73616765 0x00 0x00 0x00 0x00 0x00 0x00 0x00 0x00 0x00 0x00 0x00 0x00 0x00 0x00 0x00 0x00 0x00 0x00 0x00 0x00 0x00 0x00 0x00 0x00 0x00 0x00 0x00 0x00 0x00 0xeb00 0x18fb 0x00 0x1802 0x00 0x00 0x6d645f6d 0x656d5f75 0x73616765 0x00 0x00 0x00 0x00 0x00 0x00 0x00 0x00 0x00 0x00 0x00 0x00 0x00 0x00 0x00 0x00 0x00 0x00 0x00 0x00 0x00 0x00 0x00 0x00 0x00 0x00 0x00 0x00 0x00 0x960f 0xece1 0x00 0x1800 0x00 0x1000000 0x64726469 0x5f6d656d 0x6f727900 0x00 0x00 0x00 0x00 0x00 0x00 0x00 0x00 0x00 0x00 0x00 0x00 0x00 0x00 0x00 0x00 0x00 0x00 0x00 0x00 0x00 0x00 0x00 0x00 0x00 0x00 0x00 0x00 0x00 0x00 0x8e 0x00 0x1d00 0x00 0x00 0x61705f6d 0x645f6e63 0x5f736d65 0x6d000000 0x00 0x00 0x00 0x00 0x00 0x00 0x00 0x00 0x00 0x00 0x00 0x00 0x00 0x00 0x00 0x00 0x00 0x00 0x00 0x00 0x00 0x00 0x00 0x00 0x00 0x00 0x00 0x00 0x00 0x8a 0x00 0x9602 0x00 0x00 0x61705f6d 0x645f635f 0x736d656d 0x00 0x00 0x00 0x00 0x00 0x00 0x00 0x00 0x00 0x00 0x00 0x00 0x00 0x00 0x00 0x00 0x00 0x00 0x00 0x00 0x00 0x00 0x00 0x00 0x00 0x00 0x00 0x00 0x00 0x00 0x7a 0x00 0x9200 0x00 0x00 0x6d656469 0x6174656b 0x2c726573 0x65727665 0x2d6d656d 0x6f72792d 0x61647370 0x00 0x00 0x00 0x00 0x00 0x00 0x00 0x00 0x00 0x00 0x00 0x00 0x00 0x00 0x00 0x00 0x00 0x00 0x00 0x00 0x00 0x00 0x00 0x00 0x00 0x00 0xe6ff 0x00 0x1900 0x00 0x00 0x44504d2d 0x72657365 0x72766564 0x00 0x00 0x00 0x00 0x00 0x00 0x00 0x00 0x00 0x00 0x00 0x00 0x00 0x00 0x00 0x00 0x00 0x00 0x00 0x00 0x00 0x00 0x00 0x00 0x00 0x00 0x00 0x00 0x00 0x00 0x00 0x00 0x00 0x00 0x00 0x00 0x00 0x00 0x00 0x00 0x00 0x00 0x00 0x00 0x00 0x00 0x00 0x00 0x00 0x00 0x00 0x00 0x00 0x00 0x00 0x00 0x00 0x00 0x00 0x00 0x00 0x00 0x00 0x00 0x00 0x00 0x00 0x00 0x00 0x00 0x00 0x00 0x00 0x00 0x00 0x00 0x00 0x00 0x00 0x00 0x00 0x00 0x00 0x00 0x00 0x00 0x00 0x00 0x00 0x00 0x00 0x00 0x00 0x00 0x00 0x00 0x00 0x00 0x00 0x00 0x00 0x00 0x00 0x00 0x00 0x00 0x00 0x00 0x00 0x00 0x00 0x00 0x00 0x00 0x00 0x00 0x00 0x00 0x00 0x00 0x00 0x00 0x00 0x00 0x00 0x00 0x00 0x00 0x00 0x00 0x00 0x00 0x00 0x00 0x00 0x00 0x00 0x00 0x00 0x00 0x00 0x00 0x00 0x00 0x00 0x00 0x00 0x00 0x00 0x00 0x00 0x00 0x00 0x00 0x00 0x00 0x00 0x00 0x00 0x00 0x00 0x00 0x00 0x00 0x00 0x00 0x00 0x00 0x00 0x00 0x00 0x00 0x00 0x00 0x00 0x00 0x00 0x00 0x00 0x00 0x00 0x00 0x00 0x00 0x00 0x00 0x00 0x00 0x00 0x00 0x00 0x00 0x00 0x00 0x00 0x00 0x00 0x00 0x00 0x00 0x00 0x00 0x00 0x00 0x00 0x00 0x00 0x00 0x00 0x00 0x00 0x00 0x00 0x00 0x00 0x00 0x00 0x00 0x00 0x00 0x00 0x00 0x00 0x00 0x00 0x00 0x00 0x00 0x00 0x00 0x00 0x00 0x00 0x00 0x00 0x00 0x00 0x00 0x00 0x00 0x00 0x00 0x00 0x00 0x00 0x00 0x00 0x00 0x00 0x00 0x00 0x00 0x00 0x00 0x00 0x00 0x00 0x00 0x00 0x00 0x00 0x00 0x00 0x00 0x00 0x00 0x00 0x00 0x00 0x00 0x00 0x00 0x00 0x00 0x00 0x00 0x00 0x00 0x00 0x00 0x00 0x00 0x00 0x00 0x00 0x00 0x00 0x00 0x00 0x00 0x00 0x00 0x00 0x00 0x00 0x00 0x00 0x00 0x00 0x00 0x00 0x00 0x00 0x00 0x00 0x00 0x00 0x00 0x00 0x00 0x00 0x00 0x00 0x00 0x00 0x00 0x00 0x00 0x00 0x00 0x00 0x00 0x00 0x00 0x00 0x00 0x00 0x00 0x00 0x00 0x00 0x00 0x00 0x00 0x00 0x00 0x00 0x00 0x00 0x00 0x00 0x00 0x00 0x00 0x00 0x00 0x00 0x00 0x00 0x00 0x00 0x00 0x00 0x00 0x00 0x00 0x00 0x00 0x00 0x00 0x00 0x00 0x00 0x00 0x00 0x00 0x00 0x00 0x00 0x00 0x00 0x00 0x00 0x00 0x00 0x00 0x00 0x00 0x00 0x00 0x00 0x00 0x00 0x00 0x00 0x00 0x00 0x00 0x00 0x00 0x00 0x00 0x00 0x00 0x00 0x00 0x00 0x00 0x00 0x00 0x00 0x00 0x00 0x00 0x00 0x00 0x00 0x00 0x00 0x00 0x00 0x00 0x00 0x00 0x00 0x00 0x00 0x00 0x00 0x00 0x00 0x00 0x00 0x00 0x00 0x00 0x00 0x00 0x00 0x00 0x00 0x00 0x00 0x00 0x00 0x00 0x00 0x00 0x00 0x00 0x00 0x00 0x00 0x00 0x00 0x00 0x00 0x00 0x00 0x00 0x00 0x00 0x00 0x00 0x00 0x00 0x00 0x00 0x00 0x00 0x00 0x00 0x00 0x00 0x00 0x00 0x00 0x00 0x00 0x00 0x00 0x00 0x00 0x00 0x00 0x00 0x00 0x00 0x00 0x00 0x00 0x00 0x00 0x00 0x00 0x00 0x00 0x00 0x00 0x00 0x00 0x00 0x00 0x00 0x00 0x00 0x00 0x00 0x00 0x00 0x00 0x00 0x00 0x00 0x00 0x00 0x00 0x00 0x00 0x00 0x00 0x00 0x00 0x00 0x00 0x00 0x00 0x00 0x00 0x00 0x00 0x00 0x00 0x00 0x00 0x00 0x00 0x00 0x00 0x00 0x00 0x00 0x00 0x00 0x00 0x00 0x00 0x00 0x00 0x00 0x00 0x00 0x00 0x00 0x00 0x00 0x00 0x00 0x00 0x00 0x00 0x00 0x00 0x00 0x00 0x00 0x00 0x00 0x00 0x00 0x00 0x00 0x00 0x00 0x00 0x00 0x00 0x00 0x00 0x00 0x00 0x00 0x00 0x00 0x00 0x00 0x00 0x00 0x00 0x00 0x00 0x00 0x00 0x00 0x00 0x00 0x00 0x00 0x00 0x00 0x00 0x00 0x00 0x00 0x00 0x00 0x00 0x00 0x00 0x00 0x00 0x00 0x00 0x00 0x00 0x00 0x00 0x00 0x00 0x00 0x00 0x00 0x00 0x00 0x00 0x00 0x00 0x00 0x00 0x00 0x00 0x00 0x00 0x00 0x00 0x00 0x00 0x00 0x00 0x00 0x00 0x00 0x00 0x00 0x00 0x00 0x00 0x00 0x00 0x00 0x00 0x00 0x00 0x00 0x00 0x00 0x00 0x00 0x00 0x00 0x00 0x00 0x00 0x00 0x00 0x00 0x00 0x00 0x00 0x00 0x00 0x00 0x00 0x00 0x00 0x00 0x00 0x00 0x00 0x00 0x00 0x00 0x00 0x00 0x00 0x00 0x00 0x00 0x00 0x00 0x00 0x00 0x00 0x00 0x00 0x00 0x00 0x00 0x00 0x00 0x00 0x00 0x00 0x00 0x00 0x00 0x00 0x00 0x00 0x00 0x00 0x00 0x00 0x00 0x00 0x00 0x00 0x00 0x00 0x00 0x00 0x00 0x00 0x00 0x00 0x00 0x00 0x00 0x00 0x00 0x00 0x00 0x00 0x00 0x00 0x00 0x00 0x00 0x00 0x00 0x00 0x00 0x00 0x00 0x00 0x00 0x00 0x00 0x00 0x00 0x00 0x00 0x00 0x00 0x00 0x00 0x00 0x00 0x00 0x00 0x00 0x00 0x00 0x00 0x00 0x00 0x00 0x00 0x00 0x00 0x00 0x00 0x00 0x00 0x00 0x00 0x00 0x00 0x00 0x00 0x00 0x00 0x00 0x00 0x00 0x00 0x00 0x00 0x00 0x00 0x00 0x00 0x00 0x00 0x00 0x00 0x00 0x00 0x00 0x00 0x00 0x00 0x00 0x00 0x00 0x00 0x00 0x00 0x00 0x00 0x00 0x00 0x00 0x00 0x00 0x00 0x00 0x00 0x00 0x00 0x00 0x00 0x00 0x00 0x00 0x00 0x00 0x00 0x00 0x00 0x00 0x00 0x00 0x00 0x00 0x00 0x00 0x00 0x00 0x00 0x00 0x00 0x00 0x00 0x00 0x00 0x00 0x00 0x00 0x00 0x00 0x00 0x00 0x00 0x00 0x00 0x00 0x00 0x00 0x00 0x00 0x00 0x00 0x00 0x00 0x00 0x00 0x00 0x00 0x00 0x00 0x00 0x00 0x00 0x00 0x00 0x00 0x00 0x00 0x00 0x00 0x00 0x00 0x00 0x00 0x00 0x00 0x00 0x00 0x00 0x00 0x00 0x00 0x00 0x00 0x00 0x00 0x00 0x00 0x00 0x00 0x00 0x00 0x00 0x00 0x00 0x00 0x00 0x00 0x00 0x00 0x00 0x00 0x00 0x00 0x00 0x00 0x00 0x00 0x00 0x00 0x00 0x00 0x00 0x00 0x00 0x00 0x00 0x00 0x00 0x00 0x00 0x00 0x00 0x00 0x00 0x00 0x00 0x00 0x00 0x00 0x00 0x00 0x00 0x00 0x00 0x00 0x00 0x00 0x00 0x00 0x00 0x00 0x00 0x00 0x00 0x00 0x00 0x00 0x00 0x00 0x00 0x00 0x00 0x00 0x00 0x00 0x00 0x00 0x00 0x00 0x00 0x00 0x00 0x00 0x00 0x00 0x00 0x00 0x00 0x00 0x00 0x00 0x00 0x00 0x00 0x00 0x00 0x00 0x00 0x00 0x00 0x00 0x00 0x00 0x00 0x00 0x00 0x00 0x00 0x00 0x00 0x00 0x00 0x00 0x00 0x00 0x00 0x00 0x00 0x00 0x00 0x00 0x00 0x00 0x00 0x00 0x00 0x00 0x00 0x00 0x00 0x00 0x00 0x00 0x00 0x00 0x00 0x00 0x00 0x00 0x00 0x00 0x00 0x00 0x00 0x00 0x00 0x00 0x00 0x00 0x00 0x00 0x00 0x00 0x00 0x00 0x00 0x00 0x00 0x00 0x00 0x00 0x00 0x00 0x00 0x00 0x00 0x00 0x00 0x00 0x00 0x00 0x00 0x00 0x00 0x00 0x00 0x00 0x00 0x00 0x00 0x00 0x00 0x00 0x00 0x00 0x00 0x00 0x00 0x00 0x00 0x00 0x00 0x00 0x00 0x00 0x00 0x00 0x00 0x00 0x00 0x00 0x00 0x00 0x00 0x00 0x00 0x00 0x00 0x00 0x00 0x00 0x00 0x00 0x00 0x00 0x00 0x00 0x00 0x00 0x00 0x00 0x00 0x00 0x00 0x00 0x00 0x00 0x00 0x00 0x00 0x00 0x00 0x00 0x00 0x00 0x00 0x00 0x00 0x00 0x00 0x00 0x00 0x00 0x00 0x00 0x00 0x00 0x00 0x00 0x00 0x00 0x00 0x00 0x00 0x00 0x00 0x00 0x00 0x00 0x00 0x00 0x00 0x00 0x00 0x00 0x00 0x00 0x00 0x00 0x00 0x00 0x00 0x00 0x00 0x00 0x00 0x00 0x00 0x00 0x00 0x00 0x00 0x00 0x00 0x00 0x00 0x00 0x00 0x00 0x00 0x00 0x00 0x00 0x00 0x00 0x00 0x00 0x00 0x00 0x00 0x00 0x00 0x00 0x00 0x00 0x00 0x00 0x00 0x00 0x00 0x00 0x00 0x00 0x00 0x00 0x00 0x00 0x00 0x00 0x00 0x00 0x00 0x00 0x00 0x00 0x00 0x00 0x00 0x00 0x00 0x00 0x00 0x00 0x00 0x00 0x00 0x00 0x00 0x00 0x00 0x00 0x00 0x00 0x00 0x00 0x00 0x00 0x00 0x00 0x00 0x00 0x00 0x00 0x00 0x00 0x00 0x00 0x00 0x00 0x00 0x00 0x00 0x00 0x00 0x00 0x00 0x00 0x00 0x00 0x00 0x00 0x00 0x00 0x00 0x00 0x00 0x00 0x00 0x00 0x00 0x00 0x00 0x00 0x00 0x00 0x00 0x00 0x00 0x00 0x00 0x00 0x00 0x00 0x00 0x00 0x00 0x00 0x00 0x00 0x00 0x00 0x00 0x00 0x00 0x00 0x00 0x00 0x00 0x00 0x00 0x00 0x00 0x00 0x00 0x00 0x00 0x00 0x00 0x00 0x00 0x00 0x00 0x00 0x00 0x00 0x00 0x00 0x00 0x00 0x00 0x00 0x00 0x00 0x00 0x00 0x00 0x00 0x00 0x00 0x00 0x00 0x00 0x00 0x00 0x00 0x00 0x00 0x00 0x00 0x00 0x00 0x00 0x00 0x00 0x00 0x00 0x00 0x00 0x00 0x00 0x00 0x00 0x00 0x00 0x00 0x00 0x00 0x00 0x00 0x00 0x00 0x00 0x00 0x00 0x00 0x00 0x00 0x00 0x00 0x00 0x00 0x00 0x00 0x00 0x00 0x00 0x00 0x00 0x00 0x00 0x00 0x00 0x00 0x00 0x00 0x00 0x00 0x00 0x00 0x00 0x00 0x00 0x00 0x00 0x00 0x00 0x00 0x00 0x00 0x00 0x00 0x00 0x00 0x00 0x00 0x00 0x00 0x00 0x00 0x00 0x00 0x00 0x00 0x00 0x00 0x00 0x00 0x00 0x00 0x00 0x00 0x00 0x00 0x00 0x00 0x00 0x00 0x00 0x00 0x00 0x00 0x00 0x00 0x00 0x00 0x00 0x00 0x00 0x00 0x00 0x00 0x00 0x00 0x00 0x00 0x00 0x00 0x00 0x00 0x00 0x00 0x00 0x00 0x00 0x00 0x00 0x00 0x00 0x00 0x00 0x00 0x00 0x00 0x00 0x00 0x00 0x00 0x00 0x00 0x00 0x00 0x00 0x00 0x00 0x00 0x00 0x00 0x00 0x00 0x00 0x00 0x00 0x00 0x00 0x00 0x00 0x00 0x00 0x00 0x00 0x00 0x00 0x00 0x00 0x00 0x00 0x00 0x00 0x00 0x00 0x00 0x00 0x00 0x00 0x00 0x00 0x00 0x00 0x00 0x00 0x00 0x00 0x00 0x00 0x00 0x00 0x00 0x00 0x00 0x00 0x00 0x00 0x00 0x00 0x00 0x00 0x00 0x00 0x00 0x00 0x00 0x00 0x00 0x00 0x00 0x00 0x00 0x00 0x00 0x00 0x00 0x00 0x00 0x00 0x00 0x00 0x00 0x00 0x00 0x00 0x00 0x00 0x00 0x00 0x00 0x00 0x00 0x00 0x00 0x00 0x00 0x00 0x00 0x00 0x00 0x00 0x00 0x00 0x00 0x00 0x00 0x00 0x00 0x00 0x00 0x00 0x00 0x00 0x00 0x00 0x00 0x00 0x00 0x00 0x00 0x00 0x00 0x00 0x00 0x00 0x00 0x00 0x00 0x00 0x00 0x00 0x00 0x00 0x00 0x00 0x00 0x00 0x00 0x00 0x00 0x00 0x00 0x00 0x00 0x00 0x00 0x00 0x00 0x00 0x00 0x00 0x00 0x00 0x00 0x00 0x00 0x00 0x00 0x00 0x00 0x00 0x00 0x00 0x00 0x00 0x00 0x00 0x00 0x00 0x00 0x00 0x00 0x00 0x00 0x00 0x00 0x00 0x00 0x00 0x00 0x00 0x00 0x00 0x00 0x00 0x00 0x00 0x00 0x00 0x00 0x00 0x00 0x00 0x00 0x00 0x00 0x00 0x00 0x00 0x00 0x00 0x00 0x00 0x00 0x00 0x00 0x00 0x00 0x00 0x00 0x00 0x00 0x00 0x00 0x00 0x00 0x00 0x00 0x00 0x00 0x00 0x00 0x00 0x00 0x00 0x00 0x00 0x00 0x00 0x00 0x00 0x00 0x00 0x00 0x00 0x00 0x00 0x00 0x00 0x00 0x00 0x00 0x00 0x00 0x00 0x00 0x00 0x00 0x00 0x00 0x00 0x00 0x00 0x00 0x00 0x00 0x00 0x00 0x00 0x00 0x00 0x00 0x00 0x00 0x00 0x00 0x00 0x00 0x00 0x00 0x00 0x00 0x00 0x00 0x00 0x00 0x00 0x00 0x00 0x00 0x00 0x00 0x00 0x00 0x00 0x00 0x00 0x00 0x00 0x00 0x00 0x00 0x00 0x00 0x00 0x00 0x00 0x00 0x00 0x00 0x00 0x00 0x00 0x00 0x00 0x00 0x00 0x00 0x00 0x00 0x00 0x00 0x00 0x00 0x00 0x00 0x00 0x00 0x00 0x00 0x00 0x00 0x00 0x00 0x00 0x00 0x00 0x00 0x00 0x00 0x00 0x00 0x00 0x00 0x00 0x00 0x00 0x00 0x00 0x00 0x00 0x00 0x00 0x00 0x00 0x00 0x00 0x00 0x00 0x00 0x00 0x00 0x00 0x00 0x00 0x00 0x00 0x00 0x00 0x00 0x00 0x00 0x00 0x00 0x00 0x00 0x00 0x00 0x00 0x00 0x00 0x00 0x00 0x00 0x00 0x00 0x00 0x00 0x00 0x00 0x00 0x00 0x00 0x00 0x00 0x00 0x00 0x00 0x00 0x00 0x00 0x00 0x00 0x00 0x00 0x00 0x00 0x00 0x00 0x00 0x00 0x00 0x00 0x00 0x00 0x00 0x00 0x00 0x00 0x00 0x00 0x00 0x00 0x00 0x00 0x00 0x00 0x00 0x00 0x00 0x00 0x00 0x00 0x00 0x00 0x00 0x00 0x00 0x00 0x00 0x00 0x00 0x00 0x00 0x00 0x00 0x00 0x00 0x00 0x00 0x00 0x00 0x00 0x00 0x00 0x00 0x00 0x00 0x00 0x00 0x00 0x00 0x00 0x00 0x00 0x00 0x00 0x00 0x00 0x00 0x00 0x00 0x00 0x00 0x00 0x00 0x00 0x00 0x00 0x00 0x00 0x00 0x00 0x00 0x00 0x00 0x00 0x00 0x00 0x00 0x00 0x00 0x00 0x00 0x00 0x00 0x00 0x00 0x00 0x00 0x00 0x00 0x00 0x00 0x00 0x00 0x00 0x00 0x00 0x00 0x00 0x00 0x00 0x00 0x00 0x00 0x00 0x00 0x00 0x00 0x00 0x00 0x00 0x00 0x00 0x00 0x00 0x00 0x00 0x00 0x00 0x00 0x00 0x00 0x00 0x00 0x00 0x00 0x00 0x00 0x00 0x00 0x00 0x00 0x00 0x00 0x00 0x00 0x00 0x00 0x00 0x00 0x00 0x00 0x00 0x00 0x00 0x00 0x00 0x00 0x00 0x00 0x00 0x00 0x00 0x00 0x00 0x00 0x00 0x00 0x00 0x00 0x00 0x00 0x00 0x00 0x00 0x00 0x00 0x00 0x00 0x00 0x00 0x00 0x00 0x00 0x00 0x00 0x00 0x00 0x00 0x00 0x00 0x00 0x00 0x00 0x00 0x00 0x00 0x00 0x00 0x00 0x00 0x00 0x00 0x00 0x00 0x00 0x00 0x00 0x00 0x00 0x00 0x00 0x00 0x00 0x00 0x00 0x00 0x00 0x00 0x00 0x00 0x00 0x00 0x00 0x00 0x00 0x00 0x00 0x00 0x00 0x00 0x00 0x00 0x00 0x00 0x00 0x00 0x00 0x00 0x00 0x00 0x00 0x00 0x00 0x00 0x00 0x00 0x00 0x00 0x00 0x00 0x00 0x00 0x00 0x00 0x00 0x00 0x00 0x00 0x00 0x00 0x00 0x00 0x00 0x00 0x00 0x00 0x00 0x00 0x00 0x00 0x00 0x00 0x00 0x00 0x00 0x00 0x00 0x00 0x00 0x00 0x00 0x00 0x00 0x00 0x00 0x00 0x00 0x00 0x00 0x00 0x00 0x00 0x00 0x00 0x00 0x00 0x00 0x00 0x00 0x00 0x00 0x00 0x00 0x00 0x00 0x00 0x00 0x00 0x00 0x00 0x00 0x00 0x00 0x00 0x00 0x00 0x00 0x00 0x00 0x00 0x00 0x00 0x00 0x00 0x00 0x00 0x00 0x00 0x00 0x00 0x00 0x00 0x00 0x00 0x00 0x00 0x00 0x00 0x00 0x00 0x00 0x00 0x00 0x00 0x00 0x00 0x00 0x00 0x00 0x00 0x00 0x00 0x00 0x00 0x00 0x00 0x00 0x00 0x00 0x00 0x00 0x00 0x00 0x00 0x00 0x00 0x00 0x00 0x00 0x00 0x00 0x00 0x00 0x00 0x00 0x00 0x00 0x00 0x00 0x00 0x00 0x00 0x00 0x00 0x00 0x00 0x00 0x00 0x00 0x00 0x00 0x00 0x00 0x00 0x00 0x00 0x00 0x00 0x00 0x00 0x00 0x00 0x00 0x00 0x00 0x00 0x00 0x00 0x00 0x00 0x00 0x00 0x00 0x00 0x00 0x00 0x00 0x00 0x00 0x00 0x00 0x00 0x00 0x00 0x00 0x00 0x00 0x00 0x00 0x00 0x00 0x00 0x00 0x00 0x00 0x00 0x00 0x00 0x00 0x00 0x00 0x00 0x00 0x00 0x00 0x00 0x00 0x00 0x00 0x00 0x00 0x00 0x00 0x00 0x00 0x00 0x00 0x00 0x00 0x00 0x00 0x00 0x00 0x00 0x00 0x00 0x00 0x00 0x00 0x00 0x00 0x00 0x00 0x00 0x00 0x00 0x00 0x00 0x00 0x00 0x00 0x00 0x00 0x00 0x00 0x00 0x00 0x00 0x00 0x00 0x00 0x00 0x00 0x00 0x00 0x00 0x00 0x00 0x00 0x00 0x00 0x00 0x00 0x00 0x00 0x00 0x00 0x00 0x00 0x00 0x00 0x00 0x00 0x00 0x00 0x00 0x00 0x00 0x00 0x00 0x00 0x00 0x00 0x00 0x00 0x00 0x00 0x00 0x00 0x00 0x00 0x00 0x00 0x00 0x00 0x00 0x00 0x00 0x00 0x00 0x00 0x00 0x00 0x00 0x00 0x00 0x00 0x00 0x00 0x00 0x00 0x00 0x00 0x00 0x00 0x00 0x00 0x00 0x00 0x00 0x00 0x00 0x00 0x00 0x00 0x00 0x00 0x00 0x00 0x00 0x00 0x00 0x00 0x00 0x00 0x00 0x00 0x00 0x00 0x00 0x00 0x00 0x00 0x00 0x00 0x00 0x00 0x00 0x00 0x00 0x00 0x00 0x00 0x00 0x00 0x00 0x00 0x00 0x00 0x00 0x00 0x00 0x00 0x00 0x00 0x00 0x00 0x00 0x00 0x00 0x00 0x00 0x00 0x00 0x00 0x00 0x00 0x00 0x00 0x00 0x00 0x00 0x00 0x00 0x00 0x00 0x00 0x00 0x00 0x00 0x00 0x00 0x00 0x00 0x00 0x00 0x00 0x00 0x00 0x00 0x00 0x00 0x00 0x00 0x00 0x00 0x00 0x00 0x00 0x00 0x00 0x00 0x00 0x00 0x00 0x00 0x00 0x00 0x00 0x00 0x00 0x00 0x00 0x00 0x00 0x00 0x00 0x00 0x00 0x00 0x00 0x00 0x00 0x00 0x00 0x00 0x00 0x00 0x00 0x00 0x00 0x00 0x00 0x00 0x00 0x00 0x00 0x00 0x00 0x00 0x00 0x00 0x00 0x00 0x00 0x00 0x00 0x00 0x00 0x00 0x00 0x00 0x00 0x00 0x00 0x00 0x00 0x00 0x00 0x00 0x00 0x00 0x00 0x00 0x00 0x00 0x00 0x00 0x00 0x00 0x00 0x00 0x00 0x00 0x00 0x00 0x00 0x00 0x00 0x00 0x00 0x00 0x00 0x00 0x00 0x00 0x00 0x00 0x00 0x00 0x00 0x00 0x00 0x00 0x00 0x00 0x00 0x00 0x00 0x00 0x00 0x00 0x00 0x00 0x00 0x00 0x00 0x00 0x00 0x00 0x00 0x00 0x00 0x00 0x00 0x00 0x00 0x00 0x00 0x00 0x00 0x00 0x00 0x00 0x00 0x00 0x00 0x00 0x00 0x00 0x00 0x00 0x00 0x00 0x00 0x00 0x00 0x00 0x00 0x00 0x00 0x00 0x00 0x00 0x00 0x00 0x00 0x00 0x00 0x00 0x00 0x00 0x00 0x00 0x00 0x00 0x00 0x00 0x00 0x00 0x00 0x00 0x00 0x00 0x00 0x00 0x00 0x00 0x00 0x00 0x00 0x00 0x00 0x00 0x00 0x00 0x00 0x00 0x00 0x00 0x00 0x00 0x00 0x00 0x00 0x00 0x00 0x00 0x00 0x00 0x00 0x00 0x00 0x00 0x00 0x00 0x00 0x00 0x00 0x00 0x00 0x00 0x00 0x00 0x00 0x00 0x00 0x00 0x00 0x00 0x00 0x00 0x00 0x00 0x00 0x00 0x00 0x00 0x00 0x00 0x00 0x00 0x00 0x00 0x00 0x00 0x00 0x00 0x00 0x00 0x00 0x00 0x00 0x00 0x00 0x00 0x00 0x00 0x00 0x00 0x00 0x00 0x00 0x00 0x00 0x00 0x00 0x00 0x00 0x00 0x00 0x00 0x00 0x00 0x00 0x00 0x00 0x00 0x00 0x00 0x00 0x00 0x00 0x00 0x00 0x00 0x00 0x00 0x00 0x00 0x00 0x00 0x00 0x00 0x00 0x00 0x00 0x00 0x00 0x00 0x00 0x00 0x00 0x00 0x00 0x00 0x00 0x00 0x00 0x00 0x00 0x00 0x00 0x00 0x00 0x00 0x00 0x00 0x00 0x00 0x00 0x00 0x00 0x00 0x00 0x00 0x00 0x00 0x00 0x00 0x00 0x00 0x00 0x00 0x00 0x00 0x00 0x00 0x00 0x00 0x00 0x00 0x00 0x00 0x00 0x00 0x00 0x00 0x00 0x00 0x00 0x00 0x00 0x00 0x00 0x00 0x00 0x00 0x00 0x00 0x00 0x00 0x00 0x00 0x00 0x00 0x00 0x00 0x00 0x00 0x00 0x00 0x00 0x00 0x00 0x00 0x00 0x00 0x00 0x00 0x00 0x00 0x00 0x00 0x00 0x00 0x00 0x00 0x00 0x00 0x00 0x00 0x00 0x00 0x00 0x00 0x00 0x00 0x00 0x00 0x00 0x00 0x00 0x00 0x00 0x00 0x00 0x00 0x00 0x00 0x00 0x00 0x00 0x00 0x00 0x00 0x00 0x00 0x00 0x00 0x00 0x00 0x00 0x00 0x00 0x00 0x00 0x00 0x00 0x00 0x00 0x00 0x00 0x00 0x00 0x00 0x00 0x00 0x00 0x00 0x00 0x00 0x00 0x00 0x00 0x00 0x00 0x00 0x00 0x00 0x00 0x00 0x00 0x00 0x00 0x00 0x00 0x00 0x00 0x00 0x00 0x00 0x00 0x00 0x00 0x00 0x00 0x00 0x00 0x00 0x00 0x00 0x00 0x00 0x00 0x00 0x00 0x00 0x00 0x00 0x00 0x00 0x00 0x00 0x00 0x00 0x00 0x00 0x00 0x00 0x00 0x00 0x00 0x00 0x00 0x00 0x00 0x00 0x00 0x00 0x00 0x00 0x00 0x00 0x00 0x00 0x00 0x00 0x00 0x00 0x00 0x00 0x00 0x00 0x00 0x00 0x00 0x00 0x00 0x00 0x00 0x00 0x00 0x00 0x00 0x00 0x00 0x00 0x00 0x00 0x00 0x00 0x00 0x00 0x00 0x00 0x00 0x00 0x00 0x00 0x00 0x00 0x00 0x00 0x00 0x00 0x00 0x00 0x00 0x00 0x00 0x00 0x00 0x00 0x00 0x00 0x00 0x00 0x00 0x00 0x00 0x00 0x00 0x00 0x00 0x00 0x00 0x00 0x00 0x00 0x00 0x00 0x00 0x00 0x00 0x00 0x00 0x00 0x00 0x00 0x00 0x00 0x00 0x00 0x00 0x00 0x00 0x00 0x00 0x00 0x00 0x00 0x00 0x00 0x00 0x00 0x00 0x00 0x00 0x00 0x00 0x00 0x00 0x00 0x00 0x00 0x00 0x00 0x00 0x00 0x00 0x00 0x00 0x00 0x00 0x00 0x00 0x00 0x00 0x00 0x00 0x00 0x00 0x00 0x00 0x00 0x00 0x00 0x00 0x00 0x00 0x00 0x00 0x00 0x00 0x00 0x00 0x00 0x00 0x00 0x00 0x00 0x00 0x00 0x00 0x00 0x00 0x00 0x00 0x00 0x00 0x00 0x00 0x00 0x00 0x00 0x00 0x00 0x00 0x00 0x00 0x00 0x00 0x00 0x00 0x00 0x00 0x00 0x00 0x00 0x00 0x00 0x00 0x00 0x00 0x00 0x00 0x00 0x00 0x00 0x00 0x00 0x00 0x00 0x00 0x00 0x00 0x00 0x00 0x00 0x00 0x00 0x00 0x00 0x00 0x00 0x00 0x00 0x00 0x00 0x00 0x00 0x00 0x00 0x00 0x00 0x00 0x00 0x00 0x00 0x00 0x00 0x00 0x00 0x00 0x00 0x00 0x00 0x00 0x00 0x00 0x00 0x00 0x00 0x00 0x00 0x00 0x00 0x00 0x00 0x00 0x00 0x00 0x00 0x00 0x00 0x00 0x00 0x00 0x00 0x00 0x00 0x00 0x00 0x00 0x00 0x00 0x00 0x00 0x00 0x00 0x00 0x00 0x00 0x00 0x00 0x00 0x00 0x00 0x00 0x00 0x00 0x00 0x00 0x00 0x00 0x00 0x00 0x00 0x00 0x00 0x00 0x00 0x00 0x00 0x00 0x00 0x00 0x00 0x00 0x00 0x00 0x00 0x00 0x00 0x00 0x00 0x00 0x00 0x00 0x00 0x00 0x00 0x00 0x00 0x00 0x00 0x00 0x00 0x00 0x00 0x00 0x00 0x00 0x00 0x00 0x00 0x00 0x00 0x00 0x00 0x00 0x00 0x00 0x00 0x00 0x00 0x00 0x00 0x00 0x00 0x00 0x00 0x00 0x00 0x00 0x00 0x00 0x00 0x00 0x00 0x00 0x00 0x00 0x00 0x00 0x00 0x00 0x00 0x00 0x00 0x00 0x00 0x00 0x00 0x00 0x00 0x00 0x00 0x00 0x00 0x00 0x00 0x00 0x00 0x00 0x00 0x00 0x00 0x00 0x00 0x00 0x00 0x00 0x00 0x00 0x00 0x00 0x00 0x00 0x00 0x00 0x00 0x00 0x00 0x00 0x00 0x00 0x00 0x00 0x00 0x00 0x00 0x00 0x00 0x00 0x00 0x00 0x00 0x00 0x00 0x00 0x00 0x00 0x00 0x00 0x00 0x00 0x00 0x00 0x00 0x00 0x00 0x00 0x00 0x00 0x00 0x00 0x00 0x00 0x00 0x00 0x00 0x00 0x00 0x00 0x00 0x00 0x00 0x00 0x00 0x00 0x00 0x00 0x00 0x00 0x00 0x00 0x00 0x00 0x00 0x00 0x00 0x00 0x00 0x00 0x00 0x00 0x00 0x00 0x00 0x00 0x00 0x00 0x00 0x00 0x00 0x00 0x00 0x00 0x00 0x00 0x00 0x00 0x00 0x00 0x00 0x00 0x00 0x00 0x00 0x00 0x00 0x00 0x00 0x00 0x00 0x00 0x00 0x00>;
			orig_dram_info = <0x2000000 0x00 0x40 0x00 0x00 0x1000000 0x40 0x1000000 0x00 0x1000000 0x00 0x00 0x00 0x00 0x00 0x00 0x00 0x00>;
			device_type = "memory";
			reg = <0x00 0x40000000 0x02 0x00>;
		};

	mrdump_ext_rst: mrdump_ext_rst {
			compatible = "close, mrdump_ext_rst-eint";
			mode = "IRQ";
			status = "okay";
			phandle = <0x1be>;
			interrupt-parent = <0x02>;
			interrupts = <0x00 0x08>;
		};

	mt6360_pmu: mt6360_pmu_dts {
			status = "ok";
			mt6360,intr_gpio_num = <0x04>;
			mt6360,intr_gpio = <0x02 0x04 0x00>;
			interrupt-controller;
			#interrupt-cells = <0x02>;
			phandle = <0x03>;
			disable_lpsd = <0x01>;
	
			adc: adc {
				compatible = "mediatek,mt6360_pmu_adc";
				interrupt-parent = <0x03>;
				interrupts = <0x29 0x00 0x2b 0x00 0x2c 0x00>;
				interrupt-names = "bat_ovp_adc_evt", "adc_wakeup_evt", "adc_donei";
				#io-channel-cells = <0x01>;
				phandle = <0x04>;
			};
	
			chg {
				compatible = "mediatek,mt6360_pmu_chg";
				interrupt-parent = <0x03>;
				interrupts = <0x04 0x00 0x06 0x00 0x07 0x00 0x09 0x00 0x0c 0x00 0x0d 0x00 0x0e 0x00 0x0f 0x00 0x1b 0x00 0x1d 0x00 0x20 0x00 0x23 0x00 0x28 0x00 0x30 0x00 0x3c 0x00>;
				interrupt-names = "chg_treg_evt", "chg_mivr_evt", "pwr_rdy_evt", "chg_batsysuv_evt", "chg_vsysuv_evt", "chg_vsysov_evt", "chg_vbatov_evt", "chg_vbusov_evt", "chg_tmri", "chg_adpbadi", "chg_aiccmeasl", "wdtmri", "pumpx_donei", "attachi", "chrdet_ext_evt";
				io-channels = <0x04 0x00 0x04 0x01 0x04 0x03 0x04 0x04 0x04 0x05 0x04 0x06 0x04 0x08 0x04 0x0a>;
				io-channel-names = "USBID", "VBUSDIV5", "VSYS", "VBAT", "IBUS", "IBAT", "TEMP_JC", "TS";
				chg_name = "primary_chg";
				ichg = <0x1e8480>;
				aicr = <0x7a120>;
				mivr = <0x432380>;
				cv = <0x426030>;
				ieoc = <0x249f0>;
				safety_timer = <0x14>;
				ircmp_resistor = <0x00>;
				ircmp_vclamp = <0x7d00>;
				en_te = <0x01>;
				en_wdt = <0x01>;
				en_otg_wdt = <0x01>;
				aicc_once = <0x01>;
				post_aicc = <0x01>;
				batoc_notify = <0x00>;
			};
	
			mt6360_fled: fled {
				compatible = "mediatek,mt6360_pmu_fled";
				interrupt-parent = <0x03>;
				interrupts = <0x0b 0x00 0x4a 0x00 0x4b 0x00 0x4e 0x00 0x4f 0x00>;
				interrupt-names = "fled_chg_vinovp_evt", "fled_tx_evt", "fled_lvf_evt", "fled2_short_evt", "fled1_short_evt";
				fled_vmid_track = <0x00>;
				fled_strb_tout = <0x4e0>;
				fled1_tor_cur = <0x927c>;
				fled1_strb_cur = <0xb71b0>;
				fled2_tor_cur = <0x927c>;
				fled2_strb_cur = "", "\f5";
				phandle = <0xb5>;
			};
	
			rgbled {
				compatible = "mediatek,mt6360_pmu_rgbled";
				mt,led_name = "mt6360_pmu_led1", "mt6360_pmu_led2", "mt6360_pmu_led3", "mt6360_pmu_led4";
				mt,led_default_trigger = "cc_mode", "cc_mode", "cc_mode", "none";
			};
	
			core {
				compatible = "mediatek,mt6360_pmu_core";
				interrupt-parent = <0x03>;
				interrupts = <0x41 0x00 0x42 0x00 0x43 0x00 0x44 0x00 0x45 0x00 0x46 0x00 0x47 0x00>;
				interrupt-names = "ap_wdtrst_evt", "en_evt", "qonb_rst_evt", "mrstb_evt", "otp_evt", "vddaov_evt", "sysuv_evt";
				mren = <0x01>;
				apwdtrst_en = <0x01>;
				cc_open_sel = <0x03>;
				i2c_cc_open_tsel = <0x01>;
				ldo5_otp_en = <0x00>;
			};
		};

	mtk_lpm: mtk_lpm {
			compatible = "mediatek,mtk-lpm";
			#address-cells = <0x02>;
			#size-cells = <0x02>;
			ranges;
			suspend-method = "s2idle";
			cpupm-method = "mcu";
			irq-remain = <0x14 0x15 0x16 0x17 0x18 0x19 0x1a 0x1b 0x1c 0x1d 0x1e 0x1f 0x20 0x21 0x22>;
			resource-ctrl = <0x23 0x24 0x25 0x26 0x27>;
			constraints = <0x28 0x29 0x2a>;
			phandle = <0xeb>;
	
			cpupm_sysram: cpupm-sysram@0011b000 {
				compatible = "mediatek,cpupm-sysram";
				reg = <0x00 0x11b000 0x00 0x500>;
				phandle = <0xec>;
			};
	
			lpm_sysram: lpm_sysram@0011b500 {
				compatible = "mediatek,lpm-sysram";
				reg = <0x00 0x11b500 0x00 0x300>;
				phandle = <0xed>;
			};
	
			irq-remain-list {
	
				edge_keypad: edge_keypad {
					target = <0x2b>;
					value = <0x01 0x00 0x00 0x04>;
					phandle = <0x14>;
				};
	
				edge_mdwdt: edge_mdwdt {
					target = <0x2c>;
					value = <0x01 0x00 0x80000000 0x2000000>;
					phandle = <0x15>;
				};
	
				level_vpu_core0: level_vpu_core0 {
					target = <0x2d>;
					value = <0x00 0x00 0x00 0x00>;
					phandle = <0x16>;
				};
	
				level_vpu_core1: level_vpu_core1 {
					target = <0x2e>;
					value = <0x00 0x00 0x00 0x00>;
					phandle = <0x17>;
				};
	
				level_mtk_mdla0: level_mtk_mdla0 {
					target = <0x2f>;
					value = <0x00 0x00 0x00 0x00>;
					phandle = <0x18>;
				};
	
				level_edma0: level_edma0 {
					target = <0x30>;
					value = <0x00 0x00 0x00 0x00>;
					phandle = <0x19>;
				};
	
				level_mali0: level_mali0 {
					target = <0x31>;
					value = <0x00 0x00 0x00 0x00>;
					phandle = <0x1a>;
				};
	
				level_mali1: level_mali1 {
					target = <0x31>;
					value = <0x00 0x01 0x00 0x00>;
					phandle = <0x1b>;
				};
	
				level_mali2: level_mali2 {
					target = <0x31>;
					value = <0x00 0x02 0x00 0x00>;
					phandle = <0x1c>;
				};
	
				level_mali3: level_mali3 {
					target = <0x31>;
					value = <0x00 0x03 0x00 0x00>;
					phandle = <0x1d>;
				};
	
				level_mali4: level_mali4 {
					target = <0x31>;
					value = <0x00 0x04 0x00 0x00>;
					phandle = <0x1e>;
				};
	
				level_i2c0: level_i2c0 {
					target = <0x32>;
					value = <0x00 0x00 0x00 0x00>;
					phandle = <0x1f>;
				};
	
				level_btif_tx: level_btif_tx {
					target = <0x33>;
					value = <0x00 0x01 0x00 0x00>;
					phandle = <0x20>;
				};
	
				level_btif_rx: level_btif_rx {
					target = <0x33>;
					value = <0x00 0x02 0x00 0x00>;
					phandle = <0x21>;
				};
	
				level_bt: level_bt {
					target = <0x34>;
					value = <0x00 0x00 0x00 0x00>;
					phandle = <0x22>;
				};
			};
	
			resource-ctrl-list {
	
				bus26m: bus26m {
					id = <0x00>;
					value = <0x00>;
					phandle = <0x23>;
				};
	
				infra: infra {
					id = <0x01>;
					value = <0x00>;
					phandle = <0x24>;
				};
	
				syspll: syspll {
					id = <0x02>;
					value = <0x00>;
					phandle = <0x25>;
				};
	
				dram_s0: dram_s0 {
					id = <0x03>;
					value = <0x00>;
					phandle = <0x26>;
				};
	
				dram_s1: dram_s1 {
					id = <0x04>;
					value = <0x00>;
					phandle = <0x27>;
				};
			};
	
			constraint-list {
	
				rc_bus26m: rc_bus26m {
					id = <0x00>;
					value = <0x01>;
					phandle = <0x28>;
				};
	
				rc_syspll: rc_syspll {
					id = <0x01>;
					value = <0x01>;
					phandle = <0x29>;
				};
	
				rc_dram: rc_dram {
					id = <0x02>;
					value = <0x01>;
					phandle = <0x2a>;
				};
			};
		};

	pmu {
			compatible = "arm,armv8-pmuv3";
			interrupt-parent = <0x01>;
			interrupts = <0x01 0x07 0x04>;
		};

	psci {
			compatible = "arm,psci-1.0";
			method = "smc";
		};

	reserved_memory: reserved-memory {
			#address-cells = <0x02>;
			#size-cells = <0x02>;
			ranges;
			phandle = <0xef>;
	
			mblock-28-DPM-reserved {
				reg = <0x00 0xffe60000 0x00 0x190000>;
				no-map;
				compatible = "mediatek,DPM-reserved";
			};
	
			mblock-27-mediatek,reserve-memory-adsp {
				reg = <0x00 0x7a000000 0x00 0x920000>;
				no-map;
				compatible = "mediatek,mediatek,reserve-memory-adsp";
			};
	
			mblock-26-ap_md_c_smem {
				reg = <0x00 0x8a000000 0x00 0x2960000>;
				no-map;
				compatible = "mediatek,ap_md_c_smem";
			};
	
			mblock-25-ap_md_nc_smem {
				reg = <0x00 0x8e000000 0x00 0x1d0000>;
				no-map;
				compatible = "mediatek,ap_md_nc_smem";
			};
	
			mblock-24-drdi_memory {
				reg = <0x00 0xe1ec0000 0x00 0x180000>;
				compatible = "mediatek,drdi_memory";
			};
	
			mblock-23-md_mem_usage {
				reg = <0x00 0xfb180000 0x00 0x2180000>;
				no-map;
				compatible = "mediatek,md_mem_usage";
			};
	
			mblock-22-md_mem_usage {
				reg = <0x00 0xe4000000 0x00 0x7820000>;
				no-map;
				compatible = "mediatek,md_mem_usage";
			};
	
			mblock-21-md_mem_usage {
				reg = <0x00 0xe3000000 0x00 0x150000>;
				no-map;
				compatible = "mediatek,md_mem_usage";
			};
	
			mblock-20-md_mem_usage {
				reg = <0x00 0xe2040000 0x00 0x10000>;
				no-map;
				compatible = "mediatek,md_mem_usage";
			};
	
			mblock-19-md_mem_usage {
				reg = <0x00 0xe0000000 0x00 0x1ec0000>;
				no-map;
				compatible = "mediatek,md_mem_usage";
			};
	
			mblock-18-ccci_tag_mem {
				reg = <0x00 0xbfff0000 0x00 0x10000>;
				no-map;
				compatible = "mediatek,ccci_tag_mem";
			};
	
			mblock-17-SCP-reserved {
				reg = <0x00 0xb8400000 0x00 0x400000>;
				no-map;
				compatible = "mediatek,SCP-reserved";
			};
	
			mblock-16-SPM-reserved {
				reg = <0x00 0x77ff0000 0x00 0x10000>;
				no-map;
				compatible = "mediatek,SPM-reserved";
			};
	
			mblock-15-vpu_binary {
				reg = <0x00 0xb88d0000 0x00 0x1030000>;
				no-map;
				compatible = "mediatek,vpu_binary";
			};
	
			mblock-14-framebuffer {
				reg = <0x00 0x7dfc0000 0x00 0x1df0000>;
				compatible = "mediatek,framebuffer";
			};
	
			mblock-13-minirdump {
				reg = <0x00 0x48170000 0x00 0x10000>;
				no-map;
				compatible = "mediatek,minirdump";
			};
	
			mblock-12-pstore {
				reg = <0x00 0x48090000 0x00 0xe0000>;
				no-map;
				compatible = "mediatek,pstore";
			};
	
			mblock-11-aee_debug_kinfo {
				phandle = <0x4d020000>;
				reg = <0x00 0x48080000 0x00 0x10000>;
				no-map;
				compatible = "mediatek,aee_debug_kinfo";
			};
	
			mblock-10-PICACHU {
				reg = <0x00 0xbfd00000 0x00 0x80000>;
				no-map;
				compatible = "mediatek,PICACHU";
			};
	
			mblock-9-MCUPM-reserved {
				reg = <0x00 0x7fdb0000 0x00 0x100000>;
				no-map;
				compatible = "mediatek,MCUPM-reserved";
			};
	
			mblock-8-tee-reserved {
				reg = <0x00 0x70000000 0x00 0x3240000>;
				no-map;
				compatible = "mediatek,tee-reserved";
			};
	
			mblock-7-SSPM-reserved {
				reg = <0x00 0x7feb0000 0x00 0x100000>;
				no-map;
				compatible = "mediatek,SSPM-reserved";
			};
	
			mblock-6-atf-log-reserved {
				reg = <0x00 0xbfe00000 0x00 0x40000>;
				no-map;
				compatible = "mediatek,atf-log-reserved";
			};
	
			mblock-5-atf-reserved {
				reg = <0x00 0x48c00000 0x00 0x200000>;
				no-map;
				compatible = "mediatek,atf-reserved";
			};
	
			mblock-4-log_store {
				reg = <0x00 0x7ffbf000 0x00 0x40000>;
				compatible = "mediatek,log_store";
			};
	
			mblock-3-emi_mbist_buf {
				reg = <0x00 0x7ffff000 0x00 0x1000>;
				no-map;
				compatible = "mediatek,emi_mbist_buf";
			};
	
			mblock-2-dramc-rk1 {
				reg = <0x02 0x3ffff000 0x00 0x1000>;
				no-map;
				compatible = "mediatek,dramc-rk1";
			};
	
			mblock-1-dramc-rk0 {
				reg = <0x01 0x3ffff000 0x00 0x1000>;
				no-map;
				compatible = "mediatek,dramc-rk0";
			};
	
			zone-movable-cma-memory {
			};
	
			reserve-memory-dram_r1_dummy_read {
				alloc-ranges = <0x01 0x40000000 0x00 0xfffff000>;
				alignment = <0x00 0x1000>;
				size = <0x00 0x1000>;
				compatible = "reserve-memory-dram_r1_dummy_read";
			};
	
			reserve-memory-dram_r0_dummy_read {
				alloc-ranges = <0x00 0x5a700000 0x00 0x15900000>;
				alignment = <0x00 0x1000>;
				size = <0x00 0x1000>;
				compatible = "reserve-memory-dram_r0_dummy_read";
			};
	
			reserve-memory-mcupm_share {
				compatible = "mediatek,reserve-memory-mcupm_share";
				no-map;
				status = "okay";
				size = <0x00 0x210000>;
				alignment = <0x00 0x10000>;
				alloc-ranges = <0x00 0x40000000 0x00 0x60000000>;
			};
	
			ion-carveout-heap {
				compatible = "mediatek,ion-carveout-heap";
				no-map;
				size = <0x00 0xc000>;
				alignment = <0x00 0x1000>;
				alloc-ranges = <0x00 0x40000000 0x00 0x80000000>;
			};
	
			consys-reserve-memory {
				compatible = "mediatek,consys-reserve-memory";
				no-map;
				size = <0x00 0x780000>;
				alignment = <0x00 0x100000>;
				alloc-ranges = <0x00 0x50000000 0x00 0x40000000>;
			};
	
			reserve-memory-scp_share {
				compatible = "mediatek,reserve-memory-scp_share";
				no-map;
				size = <0x00 0x3a0000>;
				alignment = <0x00 0x1000000>;
				alloc-ranges = <0x00 0x50000000 0x00 0x40000000>;
			};
	
			reserve-memory-sspm_share {
				compatible = "mediatek,reserve-memory-sspm_share";
				no-map;
				status = <0x6f6b6179>;
				size = <0x00 0x110000>;
				alignment = <0x00 0x10000>;
				alloc-ranges = <0x00 0x40000000 0x00 0x60000000>;
			};
	
			reserve-memory-adsp_share {
				compatible = "mediatek,reserve-memory-adsp_share";
				no-map;
				size = <0x00 0x410000>;
				alloc-ranges = <0x00 0x40000000 0x00 0x40000000>;
				alignment = <0x00 0x10000>;
			};
	
			wifi_mem: wifi-reserve-memory {
				compatible = "shared-dma-pool";
				no-map;
				size = <0x00 0xf20000>;
				alignment = <0x00 0x1000000>;
				alloc-ranges = <0x00 0x40000000 0x00 0x80000000>;
				phandle = <0x7e>;
			};
	
			gps-reserve-memory {
				compatible = "mediatek,gps-reserve-memory";
				no-map;
				size = <0x00 0x100000>;
				alignment = <0x00 0x100000>;
				alloc-ranges = <0x00 0x40000000 0x00 0x80000000>;
			};
		};

	rootparam: rootparam {
			phandle = <0xe0>;
			mtk,boardid = <0x00 0x00 0x00 0x00>;
			mtk,board_name = "GIA_AN00_VG";
			mtk,product_name = "GIA-AN00";
			hardware_version = "HN1GIAM";
		};

	subpmic_pmu_eint: subpmic_pmu_eint {
			phandle = <0xf7>;
			interrupt-parent = <0x02>;
			interrupts = <0x04 0x02>;
			status = "okay";
		};

	trusty {
			compatible = "android,trusty-smc-v1";
			ranges;
			#address-cells = <0x02>;
			#size-cells = <0x02>;
			tee-id = <0x00>;
			tee-name = "trusty";
	
			mtee {
				compatible = "mediatek,trusty-mtee-v1";
			};
	
			gz-main {
				compatible = "mediatek,trusty-gz";
			};
	
			trusty-irq {
				compatible = "android,trusty-irq-v1";
				ppi-interrupt-parent = <0x01>;
			};
	
			trusty-virtio {
				compatible = "android,trusty-virtio-v1";
			};
	
			trusty-gz-log {
				compatible = "android,trusty-gz-log-v1";
			};
		};

